VERSION "dbc-export 1 2026.26.6.5"

NS_ :

BS_:

BU_: ADSP APB APP APS APSB BB BMS CC CMP CMPD CP DAS DI DIF DIR DPB EPAS3P EPAS3S EPASTP EPASTS EPBL EPBR ESP EVSE FC GTW HCML HCMR HVP IBST ICR IDB LS OCS1P ODIN PARK PCS PCS2 PLG PM PMF PMR PNCD PTC RADC RCM RCM2 RCM3 RCU SCCM SCM SCS SDCR TAS TCU TCU2 TPMS TRCM UDS UI UIS UMC USM V2G VC VCBATT VCBATT0 VCBATT1 VCBATT2 VCCC VCFRONT VCFRONT1 VCFRONT2 VCLEFT VCRIGHT VCSEAT2L VCSEAT2R VCSEC VEH

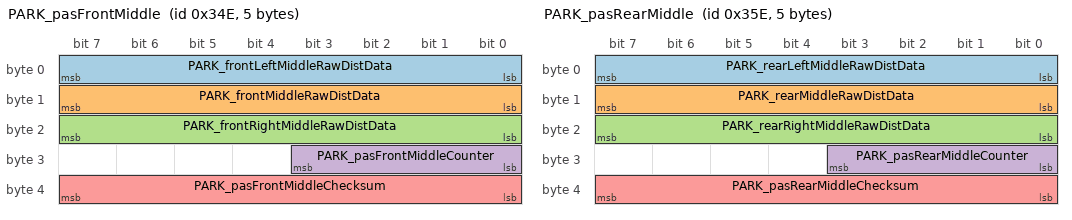
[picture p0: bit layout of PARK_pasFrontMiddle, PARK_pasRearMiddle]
BO_ 846 PARK_pasFrontMiddle: 5 PARK
 SG_ PARK_frontLeftMiddleRawDistData : 0|8@1+ (1,0) [0|254] "cm" Vector__XXX
 SG_ PARK_frontMiddleRawDistData : 8|8@1+ (1,0) [0|254] "cm" Vector__XXX
 SG_ PARK_frontRightMiddleRawDistData : 16|8@1+ (1,0) [0|254] "cm" Vector__XXX
 SG_ PARK_pasFrontMiddleCounter : 24|4@1+ (1,0) [0|15] "" Vector__XXX
 SG_ PARK_pasFrontMiddleChecksum : 32|8@1+ (1,0) [0|255] "" Vector__XXX

BO_ 862 PARK_pasRearMiddle: 5 PARK
 SG_ PARK_rearLeftMiddleRawDistData : 0|8@1+ (1,0) [0|254] "cm" Vector__XXX
 SG_ PARK_rearMiddleRawDistData : 8|8@1+ (1,0) [0|254] "cm" Vector__XXX
 SG_ PARK_rearRightMiddleRawDistData : 16|8@1+ (1,0) [0|254] "cm" Vector__XXX
 SG_ PARK_pasRearMiddleCounter : 24|4@1+ (1,0) [0|15] "" Vector__XXX
 SG_ PARK_pasRearMiddleChecksum : 32|8@1+ (1,0) [0|255] "" Vector__XXX

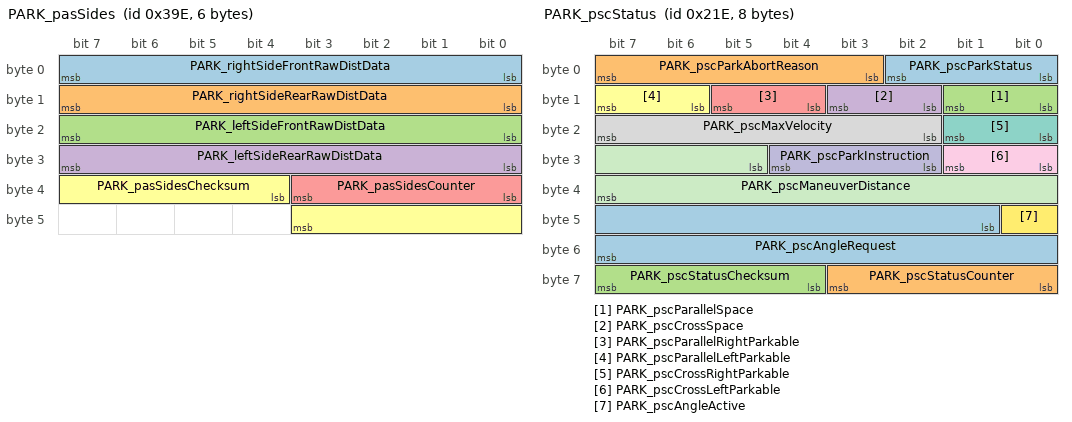
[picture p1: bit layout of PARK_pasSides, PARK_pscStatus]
BO_ 926 PARK_pasSides: 6 PARK
 SG_ PARK_rightSideFrontRawDistData : 0|8@1+ (1,0) [0|254] "cm" Vector__XXX
 SG_ PARK_rightSideRearRawDistData : 8|8@1+ (1,0) [0|254] "cm" Vector__XXX
 SG_ PARK_leftSideFrontRawDistData : 16|8@1+ (1,0) [0|254] "cm" Vector__XXX
 SG_ PARK_leftSideRearRawDistData : 24|8@1+ (1,0) [0|254] "cm" Vector__XXX
 SG_ PARK_pasSidesCounter : 32|4@1+ (1,0) [0|15] "" Vector__XXX
 SG_ PARK_pasSidesChecksum : 36|8@1+ (1,0) [0|255] "" Vector__XXX

BO_ 606 PARK_pscEnvSlot: 8 PARK
 SG_ PARK_pscEnvSlotType M : 0|2@1+ (1,0) [0|3] "" Vector__XXX
 SG_ PARK_pscLeftParallelObj1X m0 : 3|11@1+ (2,-2048) [-2048|2044] "cm" Vector__XXX
 SG_ PARK_pscLeftParallelObj1Y m0 : 14|11@1+ (2,-2048) [-2048|2044] "cm" Vector__XXX
 SG_ PARK_pscLeftParallelObj1Alpha m0 : 25|7@1+ (2,-128) [-128|124] "deg" Vector__XXX
 SG_ PARK_pscLeftParallelObj2Y m0 : 35|11@1+ (2,-2048) [-2048|2044] "cm" Vector__XXX
 SG_ PARK_pscLeftParallelObj2X m0 : 46|11@1+ (2,-2048) [-2048|2044] "cm" Vector__XXX
 SG_ PARK_pscLeftParallelObj2Alpha m0 : 57|7@1+ (2,-128) [-128|124] "deg" Vector__XXX
 SG_ PARK_pscLeftCrossObj1X m1 : 3|11@1+ (2,-2048) [-2048|2044] "cm" Vector__XXX
 SG_ PARK_pscLeftCrossObj1Y m1 : 14|11@1+ (2,-2048) [-2048|2044] "cm" Vector__XXX
 SG_ PARK_pscLeftCrossObj1Alpha m1 : 25|7@1+ (2,-128) [-128|124] "deg" Vector__XXX
 SG_ PARK_pscLeftCrossObj2Y m1 : 35|11@1+ (2,-2048) [-2048|2044] "cm" Vector__XXX
 SG_ PARK_pscLeftCrossObj2X m1 : 46|11@1+ (2,-2048) [-2048|2044] "cm" Vector__XXX
 SG_ PARK_pscLeftCrossObj2Alpha m1 : 57|7@1+ (2,-128) [-128|124] "deg" Vector__XXX
 SG_ PARK_pscRightParallelObj1X m2 : 3|11@1+ (2,-2048) [-2048|2044] "cm" Vector__XXX
 SG_ PARK_pscRightParallelObj1Y m2 : 14|11@1+ (2,-2048) [-2048|2044] "cm" Vector__XXX
 SG_ PARK_pscRightParallelObj1Alpha m2 : 25|7@1+ (2,-128) [-128|124] "deg" Vector__XXX
 SG_ PARK_pscRightParallelObj2Y m2 : 35|11@1+ (2,-2048) [-2048|2044] "cm" Vector__XXX
 SG_ PARK_pscRightParallelObj2X m2 : 46|11@1+ (2,-2048) [-2048|2044] "cm" Vector__XXX
 SG_ PARK_pscRightParallelObj2Alpha m2 : 57|7@1+ (2,-128) [-128|124] "deg" Vector__XXX
 SG_ PARK_pscRightCrossObj1X m3 : 3|11@1+ (2,-2048) [-2048|2044] "cm" Vector__XXX
 SG_ PARK_pscRightCrossObj1Y m3 : 14|11@1+ (2,-2048) [-2048|2044] "cm" Vector__XXX
 SG_ PARK_pscRightCrossObj1Alpha m3 : 25|7@1+ (2,-128) [-128|124] "deg" Vector__XXX
 SG_ PARK_pscRightCrossObj2Y m3 : 35|11@1+ (2,-2048) [-2048|2044] "cm" Vector__XXX
 SG_ PARK_pscRightCrossObj2X m3 : 46|11@1+ (2,-2048) [-2048|2044] "cm" Vector__XXX
 SG_ PARK_pscRightCrossObj2Alpha m3 : 57|7@1+ (2,-128) [-128|124] "deg" Vector__XXX

BO_ 542 PARK_pscStatus: 8 PARK
 SG_ PARK_pscParkStatus : 0|3@1+ (1,0) [0|6] "" Vector__XXX
 SG_ PARK_pscParkAbortReason : 3|5@1+ (1,0) [0|30] "" Vector__XXX
 SG_ PARK_pscParallelSpace : 8|2@1+ (1,0) [0|3] "" Vector__XXX
 SG_ PARK_pscCrossSpace : 10|2@1+ (1,0) [0|3] "" Vector__XXX
 SG_ PARK_pscParallelRightParkable : 12|2@1+ (1,0) [0|2] "" Vector__XXX
 SG_ PARK_pscParallelLeftParkable : 14|2@1+ (1,0) [0|2] "" Vector__XXX
 SG_ PARK_pscCrossRightParkable : 16|2@1+ (1,0) [0|2] "" Vector__XXX
 SG_ PARK_pscMaxVelocity : 18|6@1+ (0.1,0) [0|6.2] "kph" Vector__XXX
 SG_ PARK_pscCrossLeftParkable : 24|2@1+ (1,0) [0|2] "" Vector__XXX
 SG_ PARK_pscParkInstruction : 26|3@1+ (1,0) [0|6] "" Vector__XXX
 SG_ PARK_pscManeuverDistance : 29|11@1+ (1,0) [0|2046] "cm" Vector__XXX
 SG_ PARK_pscAngleActive : 40|1@1+ (1,0) [0|1] "" Vector__XXX
 SG_ PARK_pscAngleRequest : 41|15@1+ (0.1,-1638.4) [-1638.4|1638.3] "deg" Vector__XXX
 SG_ PARK_pscStatusCounter : 56|4@1+ (1,0) [0|15] "" Vector__XXX
 SG_ PARK_pscStatusChecksum : 60|4@1+ (1,0) [0|15] "" Vector__XXX

BO_ 590 PARK_pscVehSlot: 8 PARK
 SG_ PARK_pscVehSlotType M : 0|2@1+ (1,0) [0|3] "" Vector__XXX
 SG_ PARK_pscLeftParallelVehX m0 : 5|11@1+ (2,-2048) [-2048|2044] "cm" Vector__XXX
 SG_ PARK_pscLeftParallelVehY m0 : 16|11@1+ (2,-2048) [-2048|2044] "cm" Vector__XXX
 SG_ PARK_pscLeftParallelPsi m0 : 32|13@1+ (0.0009765625,0) [0|7.998046875] "radians" Vector__XXX
 SG_ PARK_pscLeftParallelSizeX m0 : 48|8@1+ (4,0) [0|1016] "cm" Vector__XXX
 SG_ PARK_pscLeftParallelSizeY m0 : 56|8@1+ (4,0) [0|1016] "cm" Vector__XXX
 SG_ PARK_pscLeftCrossVehX m1 : 5|11@1+ (2,-2048) [-2048|2044] "cm" Vector__XXX
 SG_ PARK_pscLeftCrossVehY m1 : 16|11@1+ (2,-2048) [-2048|2044] "cm" Vector__XXX
 SG_ PARK_pscLeftCrossPsi m1 : 32|13@1+ (0.0009765625,0) [0|7.998046875] "radians" Vector__XXX
 SG_ PARK_pscLeftCrossSizeX m1 : 48|8@1+ (4,0) [0|1016] "cm" Vector__XXX
 SG_ PARK_pscLeftCrossSizeY m1 : 56|8@1+ (4,0) [0|1016] "cm" Vector__XXX
 SG_ PARK_pscRightParallelVehX m2 : 5|11@1+ (2,-2048) [-2048|2044] "cm" Vector__XXX
 SG_ PARK_pscRightParallelVehY m2 : 16|11@1+ (2,-2048) [-2048|2044] "cm" Vector__XXX
 SG_ PARK_pscRightParallelPsi m2 : 32|13@1+ (0.0009765625,0) [0|7.998046875] "radians" Vector__XXX
 SG_ PARK_pscRightParallelSizeX m2 : 48|8@1+ (4,0) [0|1016] "cm" Vector__XXX
 SG_ PARK_pscRightParallelSizeY m2 : 56|8@1+ (4,0) [0|1016] "cm" Vector__XXX
 SG_ PARK_pscRightCrossVehX m3 : 5|11@1+ (2,-2048) [-2048|2044] "cm" Vector__XXX
 SG_ PARK_pscRightCrossVehY m3 : 16|11@1+ (2,-2048) [-2048|2044] "cm" Vector__XXX
 SG_ PARK_pscRightCrossPsi m3 : 32|13@1+ (0.0009765625,0) [0|7.998046875] "radians" Vector__XXX
 SG_ PARK_pscRightCrossSizeX m3 : 48|8@1+ (4,0) [0|1016] "cm" Vector__XXX
 SG_ PARK_pscRightCrossSizeY m3 : 56|8@1+ (4,0) [0|1016] "cm" Vector__XXX

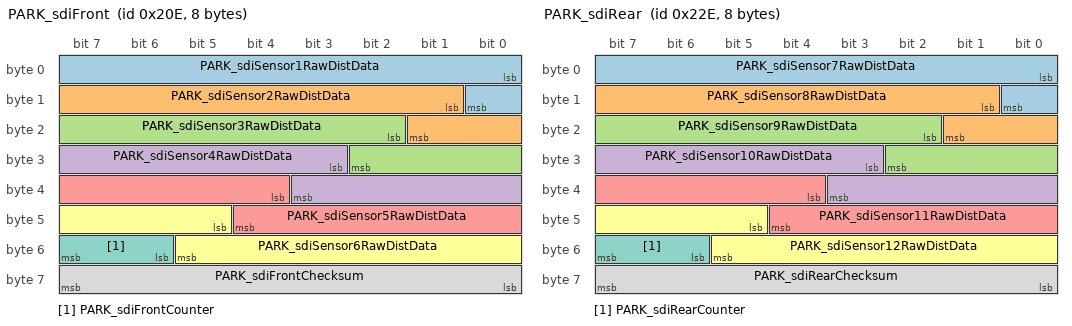
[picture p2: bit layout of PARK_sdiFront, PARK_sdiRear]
BO_ 526 PARK_sdiFront: 8 PARK
 SG_ PARK_sdiSensor1RawDistData : 0|9@1+ (1,0) [0|510] "cm" Vector__XXX
 SG_ PARK_sdiSensor2RawDistData : 9|9@1+ (1,0) [0|510] "cm" Vector__XXX
 SG_ PARK_sdiSensor3RawDistData : 18|9@1+ (1,0) [0|510] "cm" Vector__XXX
 SG_ PARK_sdiSensor4RawDistData : 27|9@1+ (1,0) [0|510] "cm" Vector__XXX
 SG_ PARK_sdiSensor5RawDistData : 36|9@1+ (1,0) [0|510] "cm" Vector__XXX
 SG_ PARK_sdiSensor6RawDistData : 45|9@1+ (1,0) [0|510] "cm" Vector__XXX
 SG_ PARK_sdiFrontCounter : 54|2@1+ (1,0) [0|3] "" Vector__XXX
 SG_ PARK_sdiFrontChecksum : 56|8@1+ (1,0) [0|255] "" Vector__XXX

BO_ 558 PARK_sdiRear: 8 PARK
 SG_ PARK_sdiSensor7RawDistData : 0|9@1+ (1,0) [0|510] "cm" Vector__XXX
 SG_ PARK_sdiSensor8RawDistData : 9|9@1+ (1,0) [0|510] "cm" Vector__XXX
 SG_ PARK_sdiSensor9RawDistData : 18|9@1+ (1,0) [0|510] "cm" Vector__XXX
 SG_ PARK_sdiSensor10RawDistData : 27|9@1+ (1,0) [0|510] "cm" Vector__XXX
 SG_ PARK_sdiSensor11RawDistData : 36|9@1+ (1,0) [0|510] "cm" Vector__XXX
 SG_ PARK_sdiSensor12RawDistData : 45|9@1+ (1,0) [0|510] "cm" Vector__XXX
 SG_ PARK_sdiRearCounter : 54|2@1+ (1,0) [0|3] "" Vector__XXX
 SG_ PARK_sdiRearChecksum : 56|8@1+ (1,0) [0|255] "" Vector__XXX

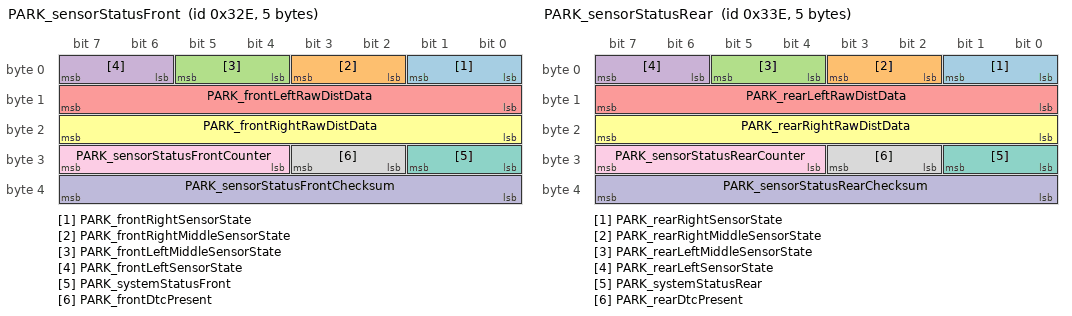
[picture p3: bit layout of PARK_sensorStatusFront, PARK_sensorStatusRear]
BO_ 814 PARK_sensorStatusFront: 5 PARK
 SG_ PARK_frontRightSensorState : 0|2@1+ (1,0) [0|2] "" Vector__XXX
 SG_ PARK_frontRightMiddleSensorState : 2|2@1+ (1,0) [0|2] "" Vector__XXX
 SG_ PARK_frontLeftMiddleSensorState : 4|2@1+ (1,0) [0|2] "" Vector__XXX
 SG_ PARK_frontLeftSensorState : 6|2@1+ (1,0) [0|2] "" Vector__XXX
 SG_ PARK_frontLeftRawDistData : 8|8@1+ (1,0) [0|254] "cm" Vector__XXX
 SG_ PARK_frontRightRawDistData : 16|8@1+ (1,0) [0|254] "cm" Vector__XXX
 SG_ PARK_systemStatusFront : 24|2@1+ (1,0) [0|2] "" Vector__XXX
 SG_ PARK_frontDtcPresent : 26|2@1+ (1,0) [0|2] "" Vector__XXX
 SG_ PARK_sensorStatusFrontCounter : 28|4@1+ (1,0) [0|15] "" Vector__XXX
 SG_ PARK_sensorStatusFrontChecksum : 32|8@1+ (1,0) [0|255] "" Vector__XXX

BO_ 830 PARK_sensorStatusRear: 5 PARK
 SG_ PARK_rearRightSensorState : 0|2@1+ (1,0) [0|2] "" Vector__XXX
 SG_ PARK_rearRightMiddleSensorState : 2|2@1+ (1,0) [0|2] "" Vector__XXX
 SG_ PARK_rearLeftMiddleSensorState : 4|2@1+ (1,0) [0|2] "" Vector__XXX
 SG_ PARK_rearLeftSensorState : 6|2@1+ (1,0) [0|2] "" Vector__XXX
 SG_ PARK_rearLeftRawDistData : 8|8@1+ (1,0) [0|254] "cm" Vector__XXX
 SG_ PARK_rearRightRawDistData : 16|8@1+ (1,0) [0|254] "cm" Vector__XXX
 SG_ PARK_systemStatusRear : 24|2@1+ (1,0) [0|2] "" Vector__XXX
 SG_ PARK_rearDtcPresent : 26|2@1+ (1,0) [0|2] "" Vector__XXX
 SG_ PARK_sensorStatusRearCounter : 28|4@1+ (1,0) [0|15] "" Vector__XXX
 SG_ PARK_sensorStatusRearChecksum : 32|8@1+ (1,0) [0|255] "" Vector__XXX

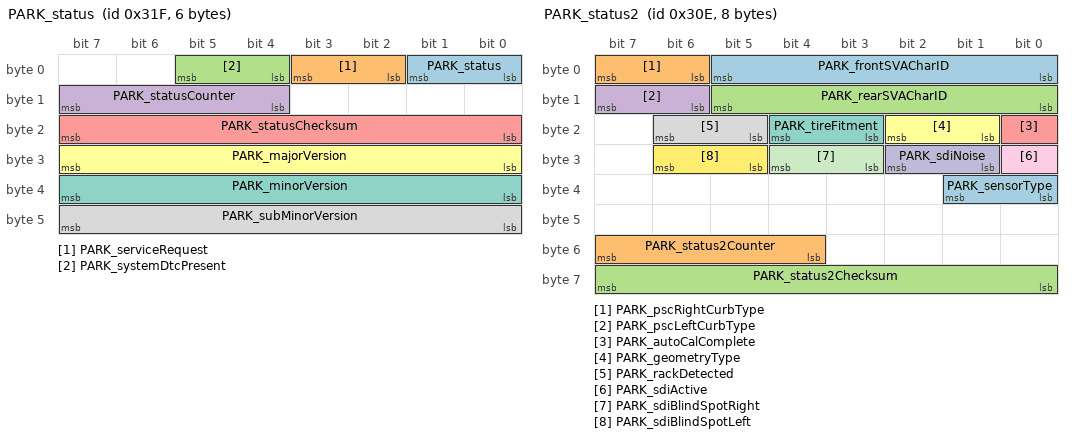
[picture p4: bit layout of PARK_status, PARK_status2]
BO_ 799 PARK_status: 6 PARK
 SG_ PARK_status : 0|2@1+ (1,0) [0|2] "" Vector__XXX
 SG_ PARK_serviceRequest : 2|2@1+ (1,0) [0|2] "" Vector__XXX
 SG_ PARK_systemDtcPresent : 4|2@1+ (1,0) [0|2] "" Vector__XXX
 SG_ PARK_statusCounter : 12|4@1+ (1,0) [0|15] "" Vector__XXX
 SG_ PARK_statusChecksum : 16|8@1+ (1,0) [0|255] "" Vector__XXX
 SG_ PARK_majorVersion : 24|8@1+ (1,0) [0|254] "" Vector__XXX
 SG_ PARK_minorVersion : 32|8@1+ (1,0) [0|254] "" Vector__XXX
 SG_ PARK_subMinorVersion : 40|8@1+ (1,0) [0|254] "" Vector__XXX

BO_ 782 PARK_status2: 8 PARK
 SG_ PARK_frontSVACharID : 0|6@1+ (1,0) [0|63] "" Vector__XXX
 SG_ PARK_pscRightCurbType : 6|2@1+ (1,0) [0|3] "" Vector__XXX
 SG_ PARK_rearSVACharID : 8|6@1+ (1,0) [0|63] "" Vector__XXX
 SG_ PARK_pscLeftCurbType : 14|2@1+ (1,0) [0|3] "" Vector__XXX
 SG_ PARK_autoCalComplete : 16|1@1+ (1,0) [0|1] "" Vector__XXX
 SG_ PARK_geometryType : 17|2@1+ (1,0) [0|3] "" Vector__XXX
 SG_ PARK_tireFitment : 19|2@1+ (1,0) [0|2] "" Vector__XXX
 SG_ PARK_rackDetected : 21|2@1+ (1,0) [0|2] "" Vector__XXX
 SG_ PARK_sdiActive : 24|1@1+ (1,0) [0|1] "" Vector__XXX
 SG_ PARK_sdiNoise : 25|2@1+ (1,0) [0|2] "" Vector__XXX
 SG_ PARK_sdiBlindSpotRight : 27|2@1+ (1,0) [0|2] "" Vector__XXX
 SG_ PARK_sdiBlindSpotLeft : 29|2@1+ (1,0) [0|2] "" Vector__XXX
 SG_ PARK_sensorType : 32|2@1+ (1,0) [0|2] "" Vector__XXX
 SG_ PARK_status2Counter : 52|4@1+ (1,0) [0|15] "" Vector__XXX
 SG_ PARK_status2Checksum : 56|8@1+ (1,0) [0|255] "" Vector__XXX

BO_ 1630 PARK_udsResponse: 8 PARK
 SG_ PARK_udsResponseData : 0|64@1+ (1,0) [0|1.84467440737e+19] "" Vector__XXX

BO_ 894 PARK_warningMatrix: 8 PARK
 SG_ PARK_matrixIndex M : 0|4@1+ (1,0) [0|15] "" Vector__XXX
 SG_ PARK_a001_s1_overTemp m0 : 4|1@1+ (1,0) [0|1] "" Vector__XXX
 SG_ PARK_a002_s1_internalFail m0 : 5|1@1+ (1,0) [0|1] "" Vector__XXX
 SG_ PARK_a003_s1_linCommError m0 : 6|1@1+ (1,0) [0|1] "" Vector__XXX
 SG_ PARK_a004_s1_blocked m0 : 7|1@1+ (1,0) [0|1] "" Vector__XXX
 SG_ PARK_a005_s1_crossTalk m0 : 8|1@1+ (1,0) [0|1] "" Vector__XXX
 SG_ PARK_a006_s2_overTemp m0 : 9|1@1+ (1,0) [0|1] "" Vector__XXX
 SG_ PARK_a007_s2_internalFail m0 : 10|1@1+ (1,0) [0|1] "" Vector__XXX
 SG_ PARK_a008_s2_linCommError m0 : 11|1@1+ (1,0) [0|1] "" Vector__XXX
 SG_ PARK_a009_s2_blocked m0 : 12|1@1+ (1,0) [0|1] "" Vector__XXX
 SG_ PARK_a010_s2_crossTalk m0 : 13|1@1+ (1,0) [0|1] "" Vector__XXX
 SG_ PARK_a011_s3_overTemp m0 : 14|1@1+ (1,0) [0|1] "" Vector__XXX
 SG_ PARK_a012_s3_internalFail m0 : 15|1@1+ (1,0) [0|1] "" Vector__XXX
 SG_ PARK_a013_s3_linCommError m0 : 16|1@1+ (1,0) [0|1] "" Vector__XXX
 SG_ PARK_a014_s3_blocked m0 : 17|1@1+ (1,0) [0|1] "" Vector__XXX
 SG_ PARK_a015_s3_crossTalk m0 : 18|1@1+ (1,0) [0|1] "" Vector__XXX
 SG_ PARK_a016_s4_overTemp m0 : 19|1@1+ (1,0) [0|1] "" Vector__XXX
 SG_ PARK_a017_s4_internalFail m0 : 20|1@1+ (1,0) [0|1] "" Vector__XXX
 SG_ PARK_a018_s4_linCommError m0 : 21|1@1+ (1,0) [0|1] "" Vector__XXX
 SG_ PARK_a019_s4_blocked m0 : 22|1@1+ (1,0) [0|1] "" Vector__XXX
 SG_ PARK_a020_s4_crossTalk m0 : 23|1@1+ (1,0) [0|1] "" Vector__XXX
 SG_ PARK_a021_s5_overTemp m0 : 24|1@1+ (1,0) [0|1] "" Vector__XXX
 SG_ PARK_a022_s5_internalFail m0 : 25|1@1+ (1,0) [0|1] "" Vector__XXX
 SG_ PARK_a023_s5_linCommError m0 : 26|1@1+ (1,0) [0|1] "" Vector__XXX
 SG_ PARK_a024_s5_blocked m0 : 27|1@1+ (1,0) [0|1] "" Vector__XXX
 SG_ PARK_a025_s5_crossTalk m0 : 28|1@1+ (1,0) [0|1] "" Vector__XXX
 SG_ PARK_a026_s6_overTemp m0 : 29|1@1+ (1,0) [0|1] "" Vector__XXX
 SG_ PARK_a027_s6_internalFail m0 : 30|1@1+ (1,0) [0|1] "" Vector__XXX
 SG_ PARK_a028_s6_linCommError m0 : 31|1@1+ (1,0) [0|1] "" Vector__XXX
 SG_ PARK_a029_s6_blocked m0 : 32|1@1+ (1,0) [0|1] "" Vector__XXX
 SG_ PARK_a030_s6_crossTalk m0 : 33|1@1+ (1,0) [0|1] "" Vector__XXX
 SG_ PARK_a031_s7_overTemp m0 : 34|1@1+ (1,0) [0|1] "" Vector__XXX
 SG_ PARK_a032_s7_internalFail m0 : 35|1@1+ (1,0) [0|1] "" Vector__XXX
 SG_ PARK_a033_s7_linCommError m0 : 36|1@1+ (1,0) [0|1] "" Vector__XXX
 SG_ PARK_a034_s7_blocked m0 : 37|1@1+ (1,0) [0|1] "" Vector__XXX
 SG_ PARK_a035_s7_crossTalk m0 : 38|1@1+ (1,0) [0|1] "" Vector__XXX
 SG_ PARK_a036_s8_overTemp m0 : 39|1@1+ (1,0) [0|1] "" Vector__XXX
 SG_ PARK_a037_s8_internalFail m0 : 40|1@1+ (1,0) [0|1] "" Vector__XXX
 SG_ PARK_a038_s8_linCommError m0 : 41|1@1+ (1,0) [0|1] "" Vector__XXX
 SG_ PARK_a039_s8_blocked m0 : 42|1@1+ (1,0) [0|1] "" Vector__XXX
 SG_ PARK_a040_s8_crossTalk m0 : 43|1@1+ (1,0) [0|1] "" Vector__XXX
 SG_ PARK_a041_s9_overTemp m0 : 44|1@1+ (1,0) [0|1] "" Vector__XXX
 SG_ PARK_a042_s9_internalFail m0 : 45|1@1+ (1,0) [0|1] "" Vector__XXX
 SG_ PARK_a043_s9_linCommError m0 : 46|1@1+ (1,0) [0|1] "" Vector__XXX
 SG_ PARK_a044_s9_blocked m0 : 47|1@1+ (1,0) [0|1] "" Vector__XXX
 SG_ PARK_a045_s9_crossTalk m0 : 48|1@1+ (1,0) [0|1] "" Vector__XXX
 SG_ PARK_a046_s10_overTemp m0 : 49|1@1+ (1,0) [0|1] "" Vector__XXX
 SG_ PARK_a047_s10_internalFail m0 : 50|1@1+ (1,0) [0|1] "" Vector__XXX
 SG_ PARK_a048_s10_linCommError m0 : 51|1@1+ (1,0) [0|1] "" Vector__XXX
 SG_ PARK_a049_s10_blocked m0 : 52|1@1+ (1,0) [0|1] "" Vector__XXX
 SG_ PARK_a050_s10_crossTalk m0 : 53|1@1+ (1,0) [0|1] "" Vector__XXX
 SG_ PARK_a051_s11_overTemp m0 : 54|1@1+ (1,0) [0|1] "" Vector__XXX
 SG_ PARK_a052_s11_internalFail m0 : 55|1@1+ (1,0) [0|1] "" Vector__XXX
 SG_ PARK_a053_s11_linCommError m0 : 56|1@1+ (1,0) [0|1] "" Vector__XXX
 SG_ PARK_a054_s11_blocked m0 : 57|1@1+ (1,0) [0|1] "" Vector__XXX
 SG_ PARK_a055_s11_crossTalk m0 : 58|1@1+ (1,0) [0|1] "" Vector__XXX
 SG_ PARK_a056_s12_overTemp m0 : 59|1@1+ (1,0) [0|1] "" Vector__XXX
 SG_ PARK_a057_s12_internalFail m0 : 60|1@1+ (1,0) [0|1] "" Vector__XXX
 SG_ PARK_a058_s12_linCommError m0 : 61|1@1+ (1,0) [0|1] "" Vector__XXX
 SG_ PARK_a059_s12_blocked m0 : 62|1@1+ (1,0) [0|1] "" Vector__XXX
 SG_ PARK_a060_s12_crossTalk m0 : 63|1@1+ (1,0) [0|1] "" Vector__XXX
 SG_ PARK_a061_ecuUnderVoltage m1 : 4|1@1+ (1,0) [0|1] "" Vector__XXX
 SG_ PARK_a062_ecuOverVoltage m1 : 5|1@1+ (1,0) [0|1] "" Vector__XXX
 SG_ PARK_a063_sensorVoltage m1 : 6|1@1+ (1,0) [0|1] "" Vector__XXX
 SG_ PARK_a064_ecuFault m1 : 7|1@1+ (1,0) [0|1] "" Vector__XXX
 SG_ PARK_a065_crcFault m1 : 8|1@1+ (1,0) [0|1] "" Vector__XXX
 SG_ PARK_a066_calibrationMissing m1 : 9|1@1+ (1,0) [0|1] "" Vector__XXX
 SG_ PARK_a067_privateCANBusOff m1 : 10|1@1+ (1,0) [0|1] "" Vector__XXX
 SG_ PARK_a068_hardwareWatchDog m1 : 11|1@1+ (1,0) [0|1] "" Vector__XXX
 SG_ PARK_a069_dasMia m1 : 12|1@1+ (1,0) [0|1] "" Vector__XXX
 SG_ PARK_a070_sccmMia m1 : 13|1@1+ (1,0) [0|1] "" Vector__XXX
 SG_ PARK_a071_diMia m1 : 14|1@1+ (1,0) [0|1] "" Vector__XXX
 SG_ PARK_a072_epasMia m1 : 15|1@1+ (1,0) [0|1] "" Vector__XXX
 SG_ PARK_a073_epbMia m1 : 16|1@1+ (1,0) [0|1] "" Vector__XXX
 SG_ PARK_a074_espMia m1 : 17|1@1+ (1,0) [0|1] "" Vector__XXX
 SG_ PARK_a075_rcmMia m1 : 18|1@1+ (1,0) [0|1] "" Vector__XXX
 SG_ PARK_a076_vcFrontMia m1 : 19|1@1+ (1,0) [0|1] "" Vector__XXX
 SG_ PARK_a077_dasError m1 : 20|1@1+ (1,0) [0|1] "" Vector__XXX
 SG_ PARK_a078_diError m1 : 21|1@1+ (1,0) [0|1] "" Vector__XXX
 SG_ PARK_a079_epasError m1 : 22|1@1+ (1,0) [0|1] "" Vector__XXX
 SG_ PARK_a080_epbError m1 : 23|1@1+ (1,0) [0|1] "" Vector__XXX
 SG_ PARK_a081_espError m1 : 24|1@1+ (1,0) [0|1] "" Vector__XXX
 SG_ PARK_a082_rcmError m1 : 25|1@1+ (1,0) [0|1] "" Vector__XXX
 SG_ PARK_a083_vcFrontError m1 : 26|1@1+ (1,0) [0|1] "" Vector__XXX
 SG_ PARK_a084_sccmError m1 : 27|1@1+ (1,0) [0|1] "" Vector__XXX
 SG_ PARK_a085_watchdogReset m1 : 28|1@1+ (1,0) [0|1] "" Vector__XXX
 SG_ PARK_a086_nvmFault m1 : 29|1@1+ (1,0) [0|1] "" Vector__XXX
 SG_ PARK_a087_sensorMismatchError m1 : 30|1@1+ (1,0) [0|1] "" Vector__XXX

BO_TX_BU_ 846 : PARK;
BO_TX_BU_ 862 : PARK;
BO_TX_BU_ 926 : PARK;
BO_TX_BU_ 606 : PARK;
BO_TX_BU_ 542 : PARK;
BO_TX_BU_ 590 : PARK;
BO_TX_BU_ 526 : PARK;
BO_TX_BU_ 558 : PARK;
BO_TX_BU_ 814 : PARK;
BO_TX_BU_ 830 : PARK;
BO_TX_BU_ 799 : PARK;
BO_TX_BU_ 782 : PARK;
BO_TX_BU_ 1630 : PARK;
BO_TX_BU_ 894 : PARK;
CM_ BO_ 846 "Parking assist sensors message: pas front middle";
CM_ SG_ 846 PARK_frontLeftMiddleRawDistData "Zone defined as -38 degrees -> +12 degrees, distance to object in units of centimeters; raw 255 = signal not available (SNA)";
CM_ SG_ 846 PARK_frontMiddleRawDistData "Zone defined as -12 degrees to +12 degrees, distance to object in units of centimeters; raw 255 = signal not available (SNA)";
CM_ SG_ 846 PARK_frontRightMiddleRawDistData "Zone defined +12 degrees to +38 degreees, distance to object in units of centimeters; raw 255 = signal not available (SNA)";
CM_ SG_ 846 PARK_pasFrontMiddleCounter "Parking assist sensors: pas front middle counter";
CM_ SG_ 846 PARK_pasFrontMiddleChecksum "Parking assist sensors: pas front middle checksum";
CM_ BO_ 862 "Parking assist sensors message: pas rear middle";
CM_ SG_ 862 PARK_rearLeftMiddleRawDistData "Zone defined as -124 degrees to -166 degrees, distance to object in units of centimeters; raw 255 = signal not available (SNA)";
CM_ SG_ 862 PARK_rearMiddleRawDistData "Zone defined as -166 degrees to +166 degrees, distance to object in units of centimeters; raw 255 = signal not available (SNA)";
CM_ SG_ 862 PARK_rearRightMiddleRawDistData "Zone defined as +166 degrees to +124 degrees, distance to object in units of centimeters; raw 255 = signal not available (SNA)";
CM_ SG_ 862 PARK_pasRearMiddleCounter "Parking assist sensors: pas rear middle counter";
CM_ SG_ 862 PARK_pasRearMiddleChecksum "Parking assist sensors: pas rear middle checksum";
CM_ BO_ 926 "Parking assist sensors message: pas sides";
CM_ SG_ 926 PARK_rightSideFrontRawDistData "Right side (from inside the car) towards the front of the car (split evenly between axles); raw 255 = signal not available (SNA)";
CM_ SG_ 926 PARK_rightSideRearRawDistData "Right side (from inside the car) towards the rear of the car (split evenly between axles); raw 255 = signal not available (SNA)";
CM_ SG_ 926 PARK_leftSideFrontRawDistData "Left side (from inside the car) towards the front of the car (split evenly between axles); raw 255 = signal not available (SNA)";
CM_ SG_ 926 PARK_leftSideRearRawDistData "Left side (from inside the car) towards the rear of the car (split evenly between axles); raw 255 = signal not available (SNA)";
CM_ SG_ 926 PARK_pasSidesCounter "Parking assist sensors: pas sides counter";
CM_ SG_ 926 PARK_pasSidesChecksum "Parking assist sensors: pas sides checksum";
CM_ BO_ 606 "Parking assist sensors message: psc env slot";
CM_ SG_ 606 PARK_pscEnvSlotType "Parking assist sensors: psc env slot type";
CM_ SG_ 606 PARK_pscLeftParallelObj1X "Parking assist sensors: psc left parallel obj1 x; raw 2047 = signal not available (SNA)";
CM_ SG_ 606 PARK_pscLeftParallelObj1Y "Parking assist sensors: psc left parallel obj1 y; raw 2047 = signal not available (SNA)";
CM_ SG_ 606 PARK_pscLeftParallelObj1Alpha "Parking assist sensors: psc left parallel obj1 alpha; raw 127 = signal not available (SNA)";
CM_ SG_ 606 PARK_pscLeftParallelObj2Y "Parking assist sensors: psc left parallel obj2 y; raw 2047 = signal not available (SNA)";
CM_ SG_ 606 PARK_pscLeftParallelObj2X "Parking assist sensors: psc left parallel obj2 x; raw 2047 = signal not available (SNA)";
CM_ SG_ 606 PARK_pscLeftParallelObj2Alpha "Parking assist sensors: psc left parallel obj2 alpha; raw 127 = signal not available (SNA)";
CM_ SG_ 606 PARK_pscLeftCrossObj1X "Parking assist sensors: psc left cross obj1 x; raw 2047 = signal not available (SNA)";
CM_ SG_ 606 PARK_pscLeftCrossObj1Y "Parking assist sensors: psc left cross obj1 y; raw 2047 = signal not available (SNA)";
CM_ SG_ 606 PARK_pscLeftCrossObj1Alpha "Parking assist sensors: psc left cross obj1 alpha; raw 127 = signal not available (SNA)";
CM_ SG_ 606 PARK_pscLeftCrossObj2Y "Parking assist sensors: psc left cross obj2 y; raw 2047 = signal not available (SNA)";
CM_ SG_ 606 PARK_pscLeftCrossObj2X "Parking assist sensors: psc left cross obj2 x; raw 2047 = signal not available (SNA)";
CM_ SG_ 606 PARK_pscLeftCrossObj2Alpha "Parking assist sensors: psc left cross obj2 alpha; raw 127 = signal not available (SNA)";
CM_ SG_ 606 PARK_pscRightParallelObj1X "Parking assist sensors: psc right parallel obj1 x; raw 2047 = signal not available (SNA)";
CM_ SG_ 606 PARK_pscRightParallelObj1Y "Parking assist sensors: psc right parallel obj1 y; raw 2047 = signal not available (SNA)";
CM_ SG_ 606 PARK_pscRightParallelObj1Alpha "Parking assist sensors: psc right parallel obj1 alpha; raw 127 = signal not available (SNA)";
CM_ SG_ 606 PARK_pscRightParallelObj2Y "Parking assist sensors: psc right parallel obj2 y; raw 2047 = signal not available (SNA)";
CM_ SG_ 606 PARK_pscRightParallelObj2X "Parking assist sensors: psc right parallel obj2 x; raw 2047 = signal not available (SNA)";
CM_ SG_ 606 PARK_pscRightParallelObj2Alpha "Parking assist sensors: psc right parallel obj2 alpha; raw 127 = signal not available (SNA)";
CM_ SG_ 606 PARK_pscRightCrossObj1X "Parking assist sensors: psc right cross obj1 x; raw 2047 = signal not available (SNA)";
CM_ SG_ 606 PARK_pscRightCrossObj1Y "Parking assist sensors: psc right cross obj1 y; raw 2047 = signal not available (SNA)";
CM_ SG_ 606 PARK_pscRightCrossObj1Alpha "Parking assist sensors: psc right cross obj1 alpha; raw 127 = signal not available (SNA)";
CM_ SG_ 606 PARK_pscRightCrossObj2Y "Parking assist sensors: psc right cross obj2 y; raw 2047 = signal not available (SNA)";
CM_ SG_ 606 PARK_pscRightCrossObj2X "Parking assist sensors: psc right cross obj2 x; raw 2047 = signal not available (SNA)";
CM_ SG_ 606 PARK_pscRightCrossObj2Alpha "Parking assist sensors: psc right cross obj2 alpha; raw 127 = signal not available (SNA)";
CM_ BO_ 542 "Parking assist sensors message: psc status";
CM_ SG_ 542 PARK_pscParkStatus "Parking assist sensors: psc park status; raw 7 = signal not available (SNA)";
CM_ SG_ 542 PARK_pscParkAbortReason "Parking assist sensors: psc park abort reason; raw 31 = signal not available (SNA)";
CM_ SG_ 542 PARK_pscParallelSpace "The existence and type of a parallel parking slot identified by the ultrasonics.";
CM_ SG_ 542 PARK_pscCrossSpace "The type and existence of perpendicular parking slot identified through the ultrasonics";
CM_ SG_ 542 PARK_pscParallelRightParkable "Whether or not there is a valid path into a parallel parking slot on the right; raw 3 = signal not available (SNA)";
CM_ SG_ 542 PARK_pscParallelLeftParkable "Whether or not there is a valid path into a parallel parking slot on the left; raw 3 = signal not available (SNA)";
CM_ SG_ 542 PARK_pscCrossRightParkable "Parking assist sensors: psc cross right parkable; raw 3 = signal not available (SNA)";
CM_ SG_ 542 PARK_pscMaxVelocity "Parking assist sensors: psc max velocity; raw 63 = signal not available (SNA)";
CM_ SG_ 542 PARK_pscCrossLeftParkable "Parking assist sensors: psc cross left parkable; raw 3 = signal not available (SNA)";
CM_ SG_ 542 PARK_pscParkInstruction "The control request from PARK ECU during autopark manuever; raw 7 = signal not available (SNA)";
CM_ SG_ 542 PARK_pscManeuverDistance "Real time updated path length from center of vehicle reference frame to desired center of vehicle at end of current parking manuever; raw 2047 = signal not available (SNA)";
CM_ SG_ 542 PARK_pscAngleActive "Parking assist sensors: psc angle active";
CM_ SG_ 542 PARK_pscAngleRequest "Parking assist sensors: psc angle request";
CM_ SG_ 542 PARK_pscStatusCounter "Parking assist sensors: psc status counter";
CM_ SG_ 542 PARK_pscStatusChecksum "Parking assist sensors: psc status checksum";
CM_ BO_ 590 "Parking assist sensors message: psc veh slot";
CM_ SG_ 590 PARK_pscVehSlotType "Parking assist sensors: psc veh slot type";
CM_ SG_ 590 PARK_pscLeftParallelVehX "Parking assist sensors: psc left parallel veh x; raw 2047 = signal not available (SNA)";
CM_ SG_ 590 PARK_pscLeftParallelVehY "Parking assist sensors: psc left parallel veh y; raw 2047 = signal not available (SNA)";
CM_ SG_ 590 PARK_pscLeftParallelPsi "Parking assist sensors: psc left parallel psi; raw 8191 = signal not available (SNA)";
CM_ SG_ 590 PARK_pscLeftParallelSizeX "Parking assist sensors: psc left parallel size x; raw 255 = signal not available (SNA)";
CM_ SG_ 590 PARK_pscLeftParallelSizeY "Parking assist sensors: psc left parallel size y; raw 255 = signal not available (SNA)";
CM_ SG_ 590 PARK_pscLeftCrossVehX "Parking assist sensors: psc left cross veh x; raw 2047 = signal not available (SNA)";
CM_ SG_ 590 PARK_pscLeftCrossVehY "Parking assist sensors: psc left cross veh y; raw 2047 = signal not available (SNA)";
CM_ SG_ 590 PARK_pscLeftCrossPsi "Parking assist sensors: psc left cross psi; raw 8191 = signal not available (SNA)";
CM_ SG_ 590 PARK_pscLeftCrossSizeX "Parking assist sensors: psc left cross size x; raw 255 = signal not available (SNA)";
CM_ SG_ 590 PARK_pscLeftCrossSizeY "Parking assist sensors: psc left cross size y; raw 255 = signal not available (SNA)";
CM_ SG_ 590 PARK_pscRightParallelVehX "Parking assist sensors: psc right parallel veh x; raw 2047 = signal not available (SNA)";
CM_ SG_ 590 PARK_pscRightParallelVehY "Parking assist sensors: psc right parallel veh y; raw 2047 = signal not available (SNA)";
CM_ SG_ 590 PARK_pscRightParallelPsi "Parking assist sensors: psc right parallel psi; raw 8191 = signal not available (SNA)";
CM_ SG_ 590 PARK_pscRightParallelSizeX "Parking assist sensors: psc right parallel size x; raw 255 = signal not available (SNA)";
CM_ SG_ 590 PARK_pscRightParallelSizeY "Parking assist sensors: psc right parallel size y; raw 255 = signal not available (SNA)";
CM_ SG_ 590 PARK_pscRightCrossVehX "Parking assist sensors: psc right cross veh x; raw 2047 = signal not available (SNA)";
CM_ SG_ 590 PARK_pscRightCrossVehY "Parking assist sensors: psc right cross veh y; raw 2047 = signal not available (SNA)";
CM_ SG_ 590 PARK_pscRightCrossPsi "Parking assist sensors: psc right cross psi; raw 8191 = signal not available (SNA)";
CM_ SG_ 590 PARK_pscRightCrossSizeX "Parking assist sensors: psc right cross size x; raw 255 = signal not available (SNA)";
CM_ SG_ 590 PARK_pscRightCrossSizeY "Parking assist sensors: psc right cross size y; raw 255 = signal not available (SNA)";
CM_ BO_ 526 "Parking assist sensors message: sdi front";
CM_ SG_ 526 PARK_sdiSensor1RawDistData "Parking assist sensors: sdi sensor1 raw dist data; raw 511 = signal not available (SNA)";
CM_ SG_ 526 PARK_sdiSensor2RawDistData "Parking assist sensors: sdi sensor2 raw dist data; raw 511 = signal not available (SNA)";
CM_ SG_ 526 PARK_sdiSensor3RawDistData "Parking assist sensors: sdi sensor3 raw dist data; raw 511 = signal not available (SNA)";
CM_ SG_ 526 PARK_sdiSensor4RawDistData "Parking assist sensors: sdi sensor4 raw dist data; raw 511 = signal not available (SNA)";
CM_ SG_ 526 PARK_sdiSensor5RawDistData "Parking assist sensors: sdi sensor5 raw dist data; raw 511 = signal not available (SNA)";
CM_ SG_ 526 PARK_sdiSensor6RawDistData "Parking assist sensors: sdi sensor6 raw dist data; raw 511 = signal not available (SNA)";
CM_ SG_ 526 PARK_sdiFrontCounter "Parking assist sensors: sdi front counter";
CM_ SG_ 526 PARK_sdiFrontChecksum "Parking assist sensors: sdi front checksum";
CM_ BO_ 558 "Parking assist sensors message: sdi rear";
CM_ SG_ 558 PARK_sdiSensor7RawDistData "Parking assist sensors: sdi sensor7 raw dist data; raw 511 = signal not available (SNA)";
CM_ SG_ 558 PARK_sdiSensor8RawDistData "Parking assist sensors: sdi sensor8 raw dist data; raw 511 = signal not available (SNA)";
CM_ SG_ 558 PARK_sdiSensor9RawDistData "Parking assist sensors: sdi sensor9 raw dist data; raw 511 = signal not available (SNA)";
CM_ SG_ 558 PARK_sdiSensor10RawDistData "Parking assist sensors: sdi sensor10 raw dist data; raw 511 = signal not available (SNA)";
CM_ SG_ 558 PARK_sdiSensor11RawDistData "Parking assist sensors: sdi sensor11 raw dist data; raw 511 = signal not available (SNA)";
CM_ SG_ 558 PARK_sdiSensor12RawDistData "Parking assist sensors: sdi sensor12 raw dist data; raw 511 = signal not available (SNA)";
CM_ SG_ 558 PARK_sdiRearCounter "Parking assist sensors: sdi rear counter";
CM_ SG_ 558 PARK_sdiRearChecksum "Parking assist sensors: sdi rear checksum";
CM_ BO_ 814 "Parking assist sensors message: sensor status front";
CM_ SG_ 814 PARK_frontRightSensorState "Reports the state of the front right ultrasonic sensor; raw 3 = signal not available (SNA)";
CM_ SG_ 814 PARK_frontRightMiddleSensorState "Reports the state of the front right middle ultrasonic sensor; raw 3 = signal not available (SNA)";
CM_ SG_ 814 PARK_frontLeftMiddleSensorState "Reports the state of the front left middle ultrasonic sensor; raw 3 = signal not available (SNA)";
CM_ SG_ 814 PARK_frontLeftSensorState "Reports the state of the front left ultrasonic sensor; raw 3 = signal not available (SNA)";
CM_ SG_ 814 PARK_frontLeftRawDistData "Zone defined as -90 degrees -> -38 degrees, distance to object in units of centimeters; raw 255 = signal not available (SNA)";
CM_ SG_ 814 PARK_frontRightRawDistData "Zone defined as +38 degrees -> +90 degrees, distance to object in units of centimeters; raw 255 = signal not available (SNA)";
CM_ SG_ 814 PARK_systemStatusFront "Parking assist sensors: system status front; raw 3 = signal not available (SNA)";
CM_ SG_ 814 PARK_frontDtcPresent "Parking assist sensors: front dtc present; raw 3 = signal not available (SNA)";
CM_ SG_ 814 PARK_sensorStatusFrontCounter "Parking assist sensors: sensor status front counter";
CM_ SG_ 814 PARK_sensorStatusFrontChecksum "Parking assist sensors: sensor status front checksum";
CM_ BO_ 830 "Parking assist sensors message: sensor status rear";
CM_ SG_ 830 PARK_rearRightSensorState "Reports the state of the rear right ultrasonic sensor; raw 3 = signal not available (SNA)";
CM_ SG_ 830 PARK_rearRightMiddleSensorState "Reports the state of the rear right middle ultrasonic sensor; raw 3 = signal not available (SNA)";
CM_ SG_ 830 PARK_rearLeftMiddleSensorState "Reports the state of the rear left middle ultrasonic sensor; raw 3 = signal not available (SNA)";
CM_ SG_ 830 PARK_rearLeftSensorState "Reports the state of the rear left ultrasonic sensor; raw 3 = signal not available (SNA)";
CM_ SG_ 830 PARK_rearLeftRawDistData "Zone defined as -90 degrees to -125 degrees, distance to object in units of centimeters; raw 255 = signal not available (SNA)";
CM_ SG_ 830 PARK_rearRightRawDistData "Zone defined as +125 degrees to +90 degrees, distance to object in units of centimeters; raw 255 = signal not available (SNA)";
CM_ SG_ 830 PARK_systemStatusRear "Parking assist sensors: system status rear; raw 3 = signal not available (SNA)";
CM_ SG_ 830 PARK_rearDtcPresent "Parking assist sensors: rear dtc present; raw 3 = signal not available (SNA)";
CM_ SG_ 830 PARK_sensorStatusRearCounter "Parking assist sensors: sensor status rear counter";
CM_ SG_ 830 PARK_sensorStatusRearChecksum "Parking assist sensors: sensor status rear checksum";
CM_ BO_ 799 "Parking assist sensors message: status";
CM_ SG_ 799 PARK_status "Indicates status of park assist function; raw 3 = signal not available (SNA)";
CM_ SG_ 799 PARK_serviceRequest "Indicates whether or not PARK sensors/ECU require service; raw 3 = signal not available (SNA)";
CM_ SG_ 799 PARK_systemDtcPresent "Boolean indicating whether or not there is a DTC present; raw 3 = signal not available (SNA)";
CM_ SG_ 799 PARK_statusCounter "Parking assist sensors: status counter";
CM_ SG_ 799 PARK_statusChecksum "Parking assist sensors: status checksum";
CM_ SG_ 799 PARK_majorVersion "Parking assist sensors: major version; raw 255 = signal not available (SNA)";
CM_ SG_ 799 PARK_minorVersion "Parking assist sensors: minor version; raw 255 = signal not available (SNA)";
CM_ SG_ 799 PARK_subMinorVersion "Parking assist sensors: sub minor version; raw 255 = signal not available (SNA)";
CM_ BO_ 782 "Parking assist sensors message: status2";
CM_ SG_ 782 PARK_frontSVACharID "Parking assist sensors: front SVA char ID";
CM_ SG_ 782 PARK_pscRightCurbType "The type of curb for the parallel parking slot on the right side.";
CM_ SG_ 782 PARK_rearSVACharID "Parking assist sensors: rear SVA char ID";
CM_ SG_ 782 PARK_pscLeftCurbType "The type of curb identified for a parallel parking space on the left.";
CM_ SG_ 782 PARK_autoCalComplete "Parking assist sensors: auto cal complete";
CM_ SG_ 782 PARK_geometryType "Parking assist sensors: geometry type";
CM_ SG_ 782 PARK_tireFitment "Parking assist sensors: tire fitment; raw 3 = signal not available (SNA)";
CM_ SG_ 782 PARK_rackDetected "Parking assist sensors: rack detected; raw 3 = signal not available (SNA)";
CM_ SG_ 782 PARK_sdiActive "Whether or not the raw sensor measurements from the ultrasonics are present and valid";
CM_ SG_ 782 PARK_sdiNoise "The output of the noise detection algorithm for raw sensor measurements, indicates if the measurements are degraded due to ambient noise; raw 3 = signal not available (SNA)";
CM_ SG_ 782 PARK_sdiBlindSpotRight "The output of the PARK ECU blindspot algorithm on the right side of the car, indicates the presence of a vehicle; raw 3 = signal not available (SNA)";
CM_ SG_ 782 PARK_sdiBlindSpotLeft "The output of the PARK ECU blindspot algorithm on the left side of the car, indicates the presence of a vehicle; raw 3 = signal not available (SNA)";
CM_ SG_ 782 PARK_sensorType "Parking assist sensors: sensor type; raw 3 = signal not available (SNA)";
CM_ SG_ 782 PARK_status2Counter "Parking assist sensors: status2 counter";
CM_ SG_ 782 PARK_status2Checksum "Parking assist sensors: status2 checksum";
CM_ BO_ 1630 "Parking assist sensors message: uds response";
CM_ SG_ 1630 PARK_udsResponseData "Parking assist sensors: uds response data";
CM_ BO_ 894 "Parking assist sensors message: warning matrix";
CM_ SG_ 894 PARK_matrixIndex "Parking assist sensors: matrix index";
CM_ SG_ 894 PARK_a001_s1_overTemp "Parking assist sensors: a001 s1 over temp";
CM_ SG_ 894 PARK_a002_s1_internalFail "Parking assist sensors: a002 s1 internal fail";
CM_ SG_ 894 PARK_a003_s1_linCommError "Parking assist sensors: a003 s1 lin comm error";
CM_ SG_ 894 PARK_a004_s1_blocked "Parking assist sensors: a004 s1 blocked";
CM_ SG_ 894 PARK_a005_s1_crossTalk "Parking assist sensors: a005 s1 cross talk";
CM_ SG_ 894 PARK_a006_s2_overTemp "Parking assist sensors: a006 s2 over temp";
CM_ SG_ 894 PARK_a007_s2_internalFail "Parking assist sensors: a007 s2 internal fail";
CM_ SG_ 894 PARK_a008_s2_linCommError "Parking assist sensors: a008 s2 lin comm error";
CM_ SG_ 894 PARK_a009_s2_blocked "Parking assist sensors: a009 s2 blocked";
CM_ SG_ 894 PARK_a010_s2_crossTalk "Parking assist sensors: a010 s2 cross talk";
CM_ SG_ 894 PARK_a011_s3_overTemp "Parking assist sensors: a011 s3 over temp";
CM_ SG_ 894 PARK_a012_s3_internalFail "Parking assist sensors: a012 s3 internal fail";
CM_ SG_ 894 PARK_a013_s3_linCommError "Parking assist sensors: a013 s3 lin comm error";
CM_ SG_ 894 PARK_a014_s3_blocked "Parking assist sensors: a014 s3 blocked";
CM_ SG_ 894 PARK_a015_s3_crossTalk "Parking assist sensors: a015 s3 cross talk";
CM_ SG_ 894 PARK_a016_s4_overTemp "Parking assist sensors: a016 s4 over temp";
CM_ SG_ 894 PARK_a017_s4_internalFail "Parking assist sensors: a017 s4 internal fail";
CM_ SG_ 894 PARK_a018_s4_linCommError "Parking assist sensors: a018 s4 lin comm error";
CM_ SG_ 894 PARK_a019_s4_blocked "Parking assist sensors: a019 s4 blocked";
CM_ SG_ 894 PARK_a020_s4_crossTalk "Parking assist sensors: a020 s4 cross talk";
CM_ SG_ 894 PARK_a021_s5_overTemp "Parking assist sensors: a021 s5 over temp";
CM_ SG_ 894 PARK_a022_s5_internalFail "Parking assist sensors: a022 s5 internal fail";
CM_ SG_ 894 PARK_a023_s5_linCommError "Parking assist sensors: a023 s5 lin comm error";
CM_ SG_ 894 PARK_a024_s5_blocked "Parking assist sensors: a024 s5 blocked";
CM_ SG_ 894 PARK_a025_s5_crossTalk "Parking assist sensors: a025 s5 cross talk";
CM_ SG_ 894 PARK_a026_s6_overTemp "Parking assist sensors: a026 s6 over temp";
CM_ SG_ 894 PARK_a027_s6_internalFail "Parking assist sensors: a027 s6 internal fail";
CM_ SG_ 894 PARK_a028_s6_linCommError "Parking assist sensors: a028 s6 lin comm error";
CM_ SG_ 894 PARK_a029_s6_blocked "Parking assist sensors: a029 s6 blocked";
CM_ SG_ 894 PARK_a030_s6_crossTalk "Parking assist sensors: a030 s6 cross talk";
CM_ SG_ 894 PARK_a031_s7_overTemp "Parking assist sensors: a031 s7 over temp";
CM_ SG_ 894 PARK_a032_s7_internalFail "Parking assist sensors: a032 s7 internal fail";
CM_ SG_ 894 PARK_a033_s7_linCommError "Parking assist sensors: a033 s7 lin comm error";
CM_ SG_ 894 PARK_a034_s7_blocked "Parking assist sensors: a034 s7 blocked";
CM_ SG_ 894 PARK_a035_s7_crossTalk "Parking assist sensors: a035 s7 cross talk";
CM_ SG_ 894 PARK_a036_s8_overTemp "Parking assist sensors: a036 s8 over temp";
CM_ SG_ 894 PARK_a037_s8_internalFail "Parking assist sensors: a037 s8 internal fail";
CM_ SG_ 894 PARK_a038_s8_linCommError "Parking assist sensors: a038 s8 lin comm error";
CM_ SG_ 894 PARK_a039_s8_blocked "Parking assist sensors: a039 s8 blocked";
CM_ SG_ 894 PARK_a040_s8_crossTalk "Parking assist sensors: a040 s8 cross talk";
CM_ SG_ 894 PARK_a041_s9_overTemp "Parking assist sensors: a041 s9 over temp";
CM_ SG_ 894 PARK_a042_s9_internalFail "Parking assist sensors: a042 s9 internal fail";
CM_ SG_ 894 PARK_a043_s9_linCommError "Parking assist sensors: a043 s9 lin comm error";
CM_ SG_ 894 PARK_a044_s9_blocked "Parking assist sensors: a044 s9 blocked";
CM_ SG_ 894 PARK_a045_s9_crossTalk "Parking assist sensors: a045 s9 cross talk";
CM_ SG_ 894 PARK_a046_s10_overTemp "Parking assist sensors: a046 s10 over temp";
CM_ SG_ 894 PARK_a047_s10_internalFail "Parking assist sensors: a047 s10 internal fail";
CM_ SG_ 894 PARK_a048_s10_linCommError "Parking assist sensors: a048 s10 lin comm error";
CM_ SG_ 894 PARK_a049_s10_blocked "Parking assist sensors: a049 s10 blocked";
CM_ SG_ 894 PARK_a050_s10_crossTalk "Parking assist sensors: a050 s10 cross talk";
CM_ SG_ 894 PARK_a051_s11_overTemp "Parking assist sensors: a051 s11 over temp";
CM_ SG_ 894 PARK_a052_s11_internalFail "Parking assist sensors: a052 s11 internal fail";
CM_ SG_ 894 PARK_a053_s11_linCommError "Parking assist sensors: a053 s11 lin comm error";
CM_ SG_ 894 PARK_a054_s11_blocked "Parking assist sensors: a054 s11 blocked";
CM_ SG_ 894 PARK_a055_s11_crossTalk "Parking assist sensors: a055 s11 cross talk";
CM_ SG_ 894 PARK_a056_s12_overTemp "Parking assist sensors: a056 s12 over temp";
CM_ SG_ 894 PARK_a057_s12_internalFail "Parking assist sensors: a057 s12 internal fail";
CM_ SG_ 894 PARK_a058_s12_linCommError "Parking assist sensors: a058 s12 lin comm error";
CM_ SG_ 894 PARK_a059_s12_blocked "Parking assist sensors: a059 s12 blocked";
CM_ SG_ 894 PARK_a060_s12_crossTalk "Parking assist sensors: a060 s12 cross talk";
CM_ SG_ 894 PARK_a061_ecuUnderVoltage "Parking assist sensors: a061 ecu under voltage";
CM_ SG_ 894 PARK_a062_ecuOverVoltage "Parking assist sensors: a062 ecu over voltage";
CM_ SG_ 894 PARK_a063_sensorVoltage "Parking assist sensors: a063 sensor voltage";
CM_ SG_ 894 PARK_a064_ecuFault "Parking assist sensors: a064 ecu fault";
CM_ SG_ 894 PARK_a065_crcFault "Parking assist sensors: a065 crc fault";
CM_ SG_ 894 PARK_a066_calibrationMissing "Parking assist sensors: a066 calibration missing";
CM_ SG_ 894 PARK_a067_privateCANBusOff "Parking assist sensors: a067 private CAN bus off";
CM_ SG_ 894 PARK_a068_hardwareWatchDog "Parking assist sensors: a068 hardware watch dog";
CM_ SG_ 894 PARK_a069_dasMia "Parking assist sensors: a069 das mia";
CM_ SG_ 894 PARK_a070_sccmMia "Parking assist sensors: a070 sccm mia";
CM_ SG_ 894 PARK_a071_diMia "Parking assist sensors: a071 di mia";
CM_ SG_ 894 PARK_a072_epasMia "Parking assist sensors: a072 epas mia";
CM_ SG_ 894 PARK_a073_epbMia "Parking assist sensors: a073 epb mia";
CM_ SG_ 894 PARK_a074_espMia "Parking assist sensors: a074 esp mia";
CM_ SG_ 894 PARK_a075_rcmMia "Parking assist sensors: a075 rcm mia";
CM_ SG_ 894 PARK_a076_vcFrontMia "Parking assist sensors: a076 vc front mia";
CM_ SG_ 894 PARK_a077_dasError "Parking assist sensors: a077 das error";
CM_ SG_ 894 PARK_a078_diError "Parking assist sensors: a078 di error";
CM_ SG_ 894 PARK_a079_epasError "Parking assist sensors: a079 epas error";
CM_ SG_ 894 PARK_a080_epbError "Parking assist sensors: a080 epb error";
CM_ SG_ 894 PARK_a081_espError "Parking assist sensors: a081 esp error";
CM_ SG_ 894 PARK_a082_rcmError "Parking assist sensors: a082 rcm error";
CM_ SG_ 894 PARK_a083_vcFrontError "Parking assist sensors: a083 vc front error";
CM_ SG_ 894 PARK_a084_sccmError "Parking assist sensors: a084 sccm error";
CM_ SG_ 894 PARK_a085_watchdogReset "Parking assist sensors: a085 watchdog reset";
CM_ SG_ 894 PARK_a086_nvmFault "Parking assist sensors: a086 nvm fault";
CM_ SG_ 894 PARK_a087_sensorMismatchError "Parking assist sensors: a087 sensor mismatch error";
BA_DEF_ BO_ "GenMsgCycleTime" INT 0 3600000;
BA_DEF_ BO_ "GenMsgSendType" ENUM "Cyclic","NotUsed","NotUsed","NotUsed","NotUsed","NotUsed","NotUsed","IfActive","NoMsgSendType","NotUsed";
BA_DEF_ BO_ "VFrameFormat" ENUM "StandardCAN","ExtendedCAN","reserved","J1939PG","reserved","reserved","reserved","reserved","reserved","reserved","reserved","reserved","reserved","reserved","StandardCAN_FD","ExtendedCAN_FD";
BA_DEF_ BO_ "CANFD_BRS" ENUM "0","1";
BA_DEF_ SG_ "GenSigSNA" STRING;
BA_DEF_ SG_ "SystemSignalLongSymbol" STRING;
BA_DEF_ SG_ "Confidence" ENUM "validated","plausible","layout-only","contradicted";
BA_DEF_DEF_ "GenMsgCycleTime" 0;
BA_DEF_DEF_ "GenMsgSendType" "NoMsgSendType";
BA_DEF_DEF_ "VFrameFormat" "StandardCAN";
BA_DEF_DEF_ "CANFD_BRS" "1";
BA_DEF_DEF_ "GenSigSNA" "";
BA_DEF_DEF_ "SystemSignalLongSymbol" "";
BA_DEF_DEF_ "Confidence" "layout-only";
BA_ "GenMsgCycleTime" BO_ 846 100;
BA_ "GenMsgSendType" BO_ 846 0;
BA_ "GenMsgCycleTime" BO_ 862 100;
BA_ "GenMsgSendType" BO_ 862 0;
BA_ "GenMsgCycleTime" BO_ 926 100;
BA_ "GenMsgSendType" BO_ 926 0;
BA_ "GenMsgCycleTime" BO_ 606 100;
BA_ "GenMsgSendType" BO_ 606 0;
BA_ "GenMsgCycleTime" BO_ 542 40;
BA_ "GenMsgSendType" BO_ 542 0;
BA_ "GenMsgCycleTime" BO_ 590 100;
BA_ "GenMsgSendType" BO_ 590 0;
BA_ "GenMsgCycleTime" BO_ 526 40;
BA_ "GenMsgSendType" BO_ 526 0;
BA_ "GenMsgCycleTime" BO_ 558 40;
BA_ "GenMsgSendType" BO_ 558 0;
BA_ "GenMsgCycleTime" BO_ 814 100;
BA_ "GenMsgSendType" BO_ 814 0;
BA_ "GenMsgCycleTime" BO_ 830 100;
BA_ "GenMsgSendType" BO_ 830 0;
BA_ "GenMsgCycleTime" BO_ 799 500;
BA_ "GenMsgSendType" BO_ 799 0;
BA_ "GenMsgCycleTime" BO_ 782 250;
BA_ "GenMsgSendType" BO_ 782 0;
BA_ "GenMsgCycleTime" BO_ 894 1000;
BA_ "GenMsgSendType" BO_ 894 0;
BA_ "Confidence" SG_ 846 PARK_frontLeftMiddleRawDistData 0;
BA_ "GenSigSNA" SG_ 846 PARK_frontLeftMiddleRawDistData "255";
BA_ "Confidence" SG_ 846 PARK_frontMiddleRawDistData 0;
BA_ "GenSigSNA" SG_ 846 PARK_frontMiddleRawDistData "255";
BA_ "Confidence" SG_ 846 PARK_frontRightMiddleRawDistData 0;
BA_ "GenSigSNA" SG_ 846 PARK_frontRightMiddleRawDistData "255";
BA_ "Confidence" SG_ 846 PARK_pasFrontMiddleCounter 0;
BA_ "Confidence" SG_ 846 PARK_pasFrontMiddleChecksum 0;
BA_ "Confidence" SG_ 862 PARK_rearLeftMiddleRawDistData 0;
BA_ "GenSigSNA" SG_ 862 PARK_rearLeftMiddleRawDistData "255";
BA_ "Confidence" SG_ 862 PARK_rearMiddleRawDistData 0;
BA_ "GenSigSNA" SG_ 862 PARK_rearMiddleRawDistData "255";
BA_ "Confidence" SG_ 862 PARK_rearRightMiddleRawDistData 0;
BA_ "GenSigSNA" SG_ 862 PARK_rearRightMiddleRawDistData "255";
BA_ "Confidence" SG_ 862 PARK_pasRearMiddleCounter 0;
BA_ "Confidence" SG_ 862 PARK_pasRearMiddleChecksum 0;
BA_ "Confidence" SG_ 926 PARK_rightSideFrontRawDistData 0;
BA_ "GenSigSNA" SG_ 926 PARK_rightSideFrontRawDistData "255";
BA_ "Confidence" SG_ 926 PARK_rightSideRearRawDistData 0;
BA_ "GenSigSNA" SG_ 926 PARK_rightSideRearRawDistData "255";
BA_ "Confidence" SG_ 926 PARK_leftSideFrontRawDistData 0;
BA_ "GenSigSNA" SG_ 926 PARK_leftSideFrontRawDistData "255";
BA_ "Confidence" SG_ 926 PARK_leftSideRearRawDistData 0;
BA_ "GenSigSNA" SG_ 926 PARK_leftSideRearRawDistData "255";
BA_ "Confidence" SG_ 926 PARK_pasSidesCounter 0;
BA_ "Confidence" SG_ 926 PARK_pasSidesChecksum 0;
BA_ "Confidence" SG_ 606 PARK_pscEnvSlotType 1;
BA_ "Confidence" SG_ 606 PARK_pscLeftParallelObj1X 0;
BA_ "GenSigSNA" SG_ 606 PARK_pscLeftParallelObj1X "2047";
BA_ "Confidence" SG_ 606 PARK_pscLeftParallelObj1Y 0;
BA_ "GenSigSNA" SG_ 606 PARK_pscLeftParallelObj1Y "2047";
BA_ "Confidence" SG_ 606 PARK_pscLeftParallelObj1Alpha 0;
BA_ "GenSigSNA" SG_ 606 PARK_pscLeftParallelObj1Alpha "127";
BA_ "Confidence" SG_ 606 PARK_pscLeftParallelObj2Y 0;
BA_ "GenSigSNA" SG_ 606 PARK_pscLeftParallelObj2Y "2047";
BA_ "Confidence" SG_ 606 PARK_pscLeftParallelObj2X 0;
BA_ "GenSigSNA" SG_ 606 PARK_pscLeftParallelObj2X "2047";
BA_ "Confidence" SG_ 606 PARK_pscLeftParallelObj2Alpha 0;
BA_ "GenSigSNA" SG_ 606 PARK_pscLeftParallelObj2Alpha "127";
BA_ "Confidence" SG_ 606 PARK_pscLeftCrossObj1X 0;
BA_ "GenSigSNA" SG_ 606 PARK_pscLeftCrossObj1X "2047";
BA_ "Confidence" SG_ 606 PARK_pscLeftCrossObj1Y 0;
BA_ "GenSigSNA" SG_ 606 PARK_pscLeftCrossObj1Y "2047";
BA_ "Confidence" SG_ 606 PARK_pscLeftCrossObj1Alpha 0;
BA_ "GenSigSNA" SG_ 606 PARK_pscLeftCrossObj1Alpha "127";
BA_ "Confidence" SG_ 606 PARK_pscLeftCrossObj2Y 0;
BA_ "GenSigSNA" SG_ 606 PARK_pscLeftCrossObj2Y "2047";
BA_ "Confidence" SG_ 606 PARK_pscLeftCrossObj2X 0;
BA_ "GenSigSNA" SG_ 606 PARK_pscLeftCrossObj2X "2047";
BA_ "Confidence" SG_ 606 PARK_pscLeftCrossObj2Alpha 0;
BA_ "GenSigSNA" SG_ 606 PARK_pscLeftCrossObj2Alpha "127";
BA_ "Confidence" SG_ 606 PARK_pscRightParallelObj1X 0;
BA_ "GenSigSNA" SG_ 606 PARK_pscRightParallelObj1X "2047";
BA_ "Confidence" SG_ 606 PARK_pscRightParallelObj1Y 0;
BA_ "GenSigSNA" SG_ 606 PARK_pscRightParallelObj1Y "2047";
BA_ "Confidence" SG_ 606 PARK_pscRightParallelObj1Alpha 0;
BA_ "GenSigSNA" SG_ 606 PARK_pscRightParallelObj1Alpha "127";
BA_ "Confidence" SG_ 606 PARK_pscRightParallelObj2Y 0;
BA_ "GenSigSNA" SG_ 606 PARK_pscRightParallelObj2Y "2047";
BA_ "Confidence" SG_ 606 PARK_pscRightParallelObj2X 0;
BA_ "GenSigSNA" SG_ 606 PARK_pscRightParallelObj2X "2047";
BA_ "Confidence" SG_ 606 PARK_pscRightParallelObj2Alpha 0;
BA_ "GenSigSNA" SG_ 606 PARK_pscRightParallelObj2Alpha "127";
BA_ "Confidence" SG_ 606 PARK_pscRightCrossObj1X 0;
BA_ "GenSigSNA" SG_ 606 PARK_pscRightCrossObj1X "2047";
BA_ "Confidence" SG_ 606 PARK_pscRightCrossObj1Y 0;
BA_ "GenSigSNA" SG_ 606 PARK_pscRightCrossObj1Y "2047";
BA_ "Confidence" SG_ 606 PARK_pscRightCrossObj1Alpha 0;
BA_ "GenSigSNA" SG_ 606 PARK_pscRightCrossObj1Alpha "127";
BA_ "Confidence" SG_ 606 PARK_pscRightCrossObj2Y 0;
BA_ "GenSigSNA" SG_ 606 PARK_pscRightCrossObj2Y "2047";
BA_ "Confidence" SG_ 606 PARK_pscRightCrossObj2X 0;
BA_ "GenSigSNA" SG_ 606 PARK_pscRightCrossObj2X "2047";
BA_ "Confidence" SG_ 606 PARK_pscRightCrossObj2Alpha 0;
BA_ "GenSigSNA" SG_ 606 PARK_pscRightCrossObj2Alpha "127";
BA_ "Confidence" SG_ 542 PARK_pscParkStatus 0;
BA_ "GenSigSNA" SG_ 542 PARK_pscParkStatus "7";
BA_ "Confidence" SG_ 542 PARK_pscParkAbortReason 0;
BA_ "GenSigSNA" SG_ 542 PARK_pscParkAbortReason "31";
BA_ "Confidence" SG_ 542 PARK_pscParallelSpace 0;
BA_ "Confidence" SG_ 542 PARK_pscCrossSpace 0;
BA_ "Confidence" SG_ 542 PARK_pscParallelRightParkable 0;
BA_ "GenSigSNA" SG_ 542 PARK_pscParallelRightParkable "3";
BA_ "Confidence" SG_ 542 PARK_pscParallelLeftParkable 0;
BA_ "GenSigSNA" SG_ 542 PARK_pscParallelLeftParkable "3";
BA_ "Confidence" SG_ 542 PARK_pscCrossRightParkable 0;
BA_ "GenSigSNA" SG_ 542 PARK_pscCrossRightParkable "3";
BA_ "Confidence" SG_ 542 PARK_pscMaxVelocity 0;
BA_ "GenSigSNA" SG_ 542 PARK_pscMaxVelocity "63";
BA_ "Confidence" SG_ 542 PARK_pscCrossLeftParkable 0;
BA_ "GenSigSNA" SG_ 542 PARK_pscCrossLeftParkable "3";
BA_ "Confidence" SG_ 542 PARK_pscParkInstruction 0;
BA_ "GenSigSNA" SG_ 542 PARK_pscParkInstruction "7";
BA_ "Confidence" SG_ 542 PARK_pscManeuverDistance 0;
BA_ "GenSigSNA" SG_ 542 PARK_pscManeuverDistance "2047";
BA_ "Confidence" SG_ 542 PARK_pscAngleActive 0;
BA_ "Confidence" SG_ 542 PARK_pscAngleRequest 0;
BA_ "Confidence" SG_ 542 PARK_pscStatusCounter 0;
BA_ "Confidence" SG_ 542 PARK_pscStatusChecksum 0;
BA_ "Confidence" SG_ 590 PARK_pscVehSlotType 1;
BA_ "Confidence" SG_ 590 PARK_pscLeftParallelVehX 0;
BA_ "GenSigSNA" SG_ 590 PARK_pscLeftParallelVehX "2047";
BA_ "Confidence" SG_ 590 PARK_pscLeftParallelVehY 0;
BA_ "GenSigSNA" SG_ 590 PARK_pscLeftParallelVehY "2047";
BA_ "Confidence" SG_ 590 PARK_pscLeftParallelPsi 0;
BA_ "GenSigSNA" SG_ 590 PARK_pscLeftParallelPsi "8191";
BA_ "Confidence" SG_ 590 PARK_pscLeftParallelSizeX 0;
BA_ "GenSigSNA" SG_ 590 PARK_pscLeftParallelSizeX "255";
BA_ "Confidence" SG_ 590 PARK_pscLeftParallelSizeY 0;
BA_ "GenSigSNA" SG_ 590 PARK_pscLeftParallelSizeY "255";
BA_ "Confidence" SG_ 590 PARK_pscLeftCrossVehX 0;
BA_ "GenSigSNA" SG_ 590 PARK_pscLeftCrossVehX "2047";
BA_ "Confidence" SG_ 590 PARK_pscLeftCrossVehY 0;
BA_ "GenSigSNA" SG_ 590 PARK_pscLeftCrossVehY "2047";
BA_ "Confidence" SG_ 590 PARK_pscLeftCrossPsi 0;
BA_ "GenSigSNA" SG_ 590 PARK_pscLeftCrossPsi "8191";
BA_ "Confidence" SG_ 590 PARK_pscLeftCrossSizeX 0;
BA_ "GenSigSNA" SG_ 590 PARK_pscLeftCrossSizeX "255";
BA_ "Confidence" SG_ 590 PARK_pscLeftCrossSizeY 0;
BA_ "GenSigSNA" SG_ 590 PARK_pscLeftCrossSizeY "255";
BA_ "Confidence" SG_ 590 PARK_pscRightParallelVehX 0;
BA_ "GenSigSNA" SG_ 590 PARK_pscRightParallelVehX "2047";
BA_ "Confidence" SG_ 590 PARK_pscRightParallelVehY 0;
BA_ "GenSigSNA" SG_ 590 PARK_pscRightParallelVehY "2047";
BA_ "Confidence" SG_ 590 PARK_pscRightParallelPsi 0;
BA_ "GenSigSNA" SG_ 590 PARK_pscRightParallelPsi "8191";
BA_ "Confidence" SG_ 590 PARK_pscRightParallelSizeX 0;
BA_ "GenSigSNA" SG_ 590 PARK_pscRightParallelSizeX "255";
BA_ "Confidence" SG_ 590 PARK_pscRightParallelSizeY 0;
BA_ "GenSigSNA" SG_ 590 PARK_pscRightParallelSizeY "255";
BA_ "Confidence" SG_ 590 PARK_pscRightCrossVehX 0;
BA_ "GenSigSNA" SG_ 590 PARK_pscRightCrossVehX "2047";
BA_ "Confidence" SG_ 590 PARK_pscRightCrossVehY 0;
BA_ "GenSigSNA" SG_ 590 PARK_pscRightCrossVehY "2047";
BA_ "Confidence" SG_ 590 PARK_pscRightCrossPsi 0;
BA_ "GenSigSNA" SG_ 590 PARK_pscRightCrossPsi "8191";
BA_ "Confidence" SG_ 590 PARK_pscRightCrossSizeX 0;
BA_ "GenSigSNA" SG_ 590 PARK_pscRightCrossSizeX "255";
BA_ "Confidence" SG_ 590 PARK_pscRightCrossSizeY 0;
BA_ "GenSigSNA" SG_ 590 PARK_pscRightCrossSizeY "255";
BA_ "Confidence" SG_ 526 PARK_sdiSensor1RawDistData 0;
BA_ "GenSigSNA" SG_ 526 PARK_sdiSensor1RawDistData "511";
BA_ "Confidence" SG_ 526 PARK_sdiSensor2RawDistData 0;
BA_ "GenSigSNA" SG_ 526 PARK_sdiSensor2RawDistData "511";
BA_ "Confidence" SG_ 526 PARK_sdiSensor3RawDistData 0;
BA_ "GenSigSNA" SG_ 526 PARK_sdiSensor3RawDistData "511";
BA_ "Confidence" SG_ 526 PARK_sdiSensor4RawDistData 0;
BA_ "GenSigSNA" SG_ 526 PARK_sdiSensor4RawDistData "511";
BA_ "Confidence" SG_ 526 PARK_sdiSensor5RawDistData 0;
BA_ "GenSigSNA" SG_ 526 PARK_sdiSensor5RawDistData "511";
BA_ "Confidence" SG_ 526 PARK_sdiSensor6RawDistData 0;
BA_ "GenSigSNA" SG_ 526 PARK_sdiSensor6RawDistData "511";
BA_ "Confidence" SG_ 526 PARK_sdiFrontCounter 0;
BA_ "Confidence" SG_ 526 PARK_sdiFrontChecksum 0;
BA_ "Confidence" SG_ 558 PARK_sdiSensor7RawDistData 0;
BA_ "GenSigSNA" SG_ 558 PARK_sdiSensor7RawDistData "511";
BA_ "Confidence" SG_ 558 PARK_sdiSensor8RawDistData 0;
BA_ "GenSigSNA" SG_ 558 PARK_sdiSensor8RawDistData "511";
BA_ "Confidence" SG_ 558 PARK_sdiSensor9RawDistData 0;
BA_ "GenSigSNA" SG_ 558 PARK_sdiSensor9RawDistData "511";
BA_ "Confidence" SG_ 558 PARK_sdiSensor10RawDistData 0;
BA_ "GenSigSNA" SG_ 558 PARK_sdiSensor10RawDistData "511";
BA_ "Confidence" SG_ 558 PARK_sdiSensor11RawDistData 0;
BA_ "GenSigSNA" SG_ 558 PARK_sdiSensor11RawDistData "511";
BA_ "Confidence" SG_ 558 PARK_sdiSensor12RawDistData 0;
BA_ "GenSigSNA" SG_ 558 PARK_sdiSensor12RawDistData "511";
BA_ "Confidence" SG_ 558 PARK_sdiRearCounter 0;
BA_ "Confidence" SG_ 558 PARK_sdiRearChecksum 0;
BA_ "Confidence" SG_ 814 PARK_frontRightSensorState 0;
BA_ "GenSigSNA" SG_ 814 PARK_frontRightSensorState "3";
BA_ "Confidence" SG_ 814 PARK_frontRightMiddleSensorState 0;
BA_ "GenSigSNA" SG_ 814 PARK_frontRightMiddleSensorState "3";
BA_ "Confidence" SG_ 814 PARK_frontLeftMiddleSensorState 0;
BA_ "GenSigSNA" SG_ 814 PARK_frontLeftMiddleSensorState "3";
BA_ "Confidence" SG_ 814 PARK_frontLeftSensorState 0;
BA_ "GenSigSNA" SG_ 814 PARK_frontLeftSensorState "3";
BA_ "Confidence" SG_ 814 PARK_frontLeftRawDistData 0;
BA_ "GenSigSNA" SG_ 814 PARK_frontLeftRawDistData "255";
BA_ "Confidence" SG_ 814 PARK_frontRightRawDistData 0;
BA_ "GenSigSNA" SG_ 814 PARK_frontRightRawDistData "255";
BA_ "Confidence" SG_ 814 PARK_systemStatusFront 0;
BA_ "GenSigSNA" SG_ 814 PARK_systemStatusFront "3";
BA_ "Confidence" SG_ 814 PARK_frontDtcPresent 0;
BA_ "GenSigSNA" SG_ 814 PARK_frontDtcPresent "3";
BA_ "Confidence" SG_ 814 PARK_sensorStatusFrontCounter 0;
BA_ "Confidence" SG_ 814 PARK_sensorStatusFrontChecksum 0;
BA_ "Confidence" SG_ 830 PARK_rearRightSensorState 0;
BA_ "GenSigSNA" SG_ 830 PARK_rearRightSensorState "3";
BA_ "Confidence" SG_ 830 PARK_rearRightMiddleSensorState 0;
BA_ "GenSigSNA" SG_ 830 PARK_rearRightMiddleSensorState "3";
BA_ "Confidence" SG_ 830 PARK_rearLeftMiddleSensorState 0;
BA_ "GenSigSNA" SG_ 830 PARK_rearLeftMiddleSensorState "3";
BA_ "Confidence" SG_ 830 PARK_rearLeftSensorState 0;
BA_ "GenSigSNA" SG_ 830 PARK_rearLeftSensorState "3";
BA_ "Confidence" SG_ 830 PARK_rearLeftRawDistData 0;
BA_ "GenSigSNA" SG_ 830 PARK_rearLeftRawDistData "255";
BA_ "Confidence" SG_ 830 PARK_rearRightRawDistData 0;
BA_ "GenSigSNA" SG_ 830 PARK_rearRightRawDistData "255";
BA_ "Confidence" SG_ 830 PARK_systemStatusRear 0;
BA_ "GenSigSNA" SG_ 830 PARK_systemStatusRear "3";
BA_ "Confidence" SG_ 830 PARK_rearDtcPresent 0;
BA_ "GenSigSNA" SG_ 830 PARK_rearDtcPresent "3";
BA_ "Confidence" SG_ 830 PARK_sensorStatusRearCounter 0;
BA_ "Confidence" SG_ 830 PARK_sensorStatusRearChecksum 0;
BA_ "Confidence" SG_ 799 PARK_status 0;
BA_ "GenSigSNA" SG_ 799 PARK_status "3";
BA_ "Confidence" SG_ 799 PARK_serviceRequest 0;
BA_ "GenSigSNA" SG_ 799 PARK_serviceRequest "3";
BA_ "Confidence" SG_ 799 PARK_systemDtcPresent 0;
BA_ "GenSigSNA" SG_ 799 PARK_systemDtcPresent "3";
BA_ "Confidence" SG_ 799 PARK_statusCounter 0;
BA_ "Confidence" SG_ 799 PARK_statusChecksum 0;
BA_ "Confidence" SG_ 799 PARK_majorVersion 0;
BA_ "GenSigSNA" SG_ 799 PARK_majorVersion "255";
BA_ "Confidence" SG_ 799 PARK_minorVersion 0;
BA_ "GenSigSNA" SG_ 799 PARK_minorVersion "255";
BA_ "Confidence" SG_ 799 PARK_subMinorVersion 0;
BA_ "GenSigSNA" SG_ 799 PARK_subMinorVersion "255";
BA_ "Confidence" SG_ 782 PARK_frontSVACharID 0;
BA_ "Confidence" SG_ 782 PARK_pscRightCurbType 0;
BA_ "Confidence" SG_ 782 PARK_rearSVACharID 0;
BA_ "Confidence" SG_ 782 PARK_pscLeftCurbType 0;
BA_ "Confidence" SG_ 782 PARK_autoCalComplete 0;
BA_ "Confidence" SG_ 782 PARK_geometryType 0;
BA_ "Confidence" SG_ 782 PARK_tireFitment 0;
BA_ "GenSigSNA" SG_ 782 PARK_tireFitment "3";
BA_ "Confidence" SG_ 782 PARK_rackDetected 0;
BA_ "GenSigSNA" SG_ 782 PARK_rackDetected "3";
BA_ "Confidence" SG_ 782 PARK_sdiActive 0;
BA_ "Confidence" SG_ 782 PARK_sdiNoise 0;
BA_ "GenSigSNA" SG_ 782 PARK_sdiNoise "3";
BA_ "Confidence" SG_ 782 PARK_sdiBlindSpotRight 0;
BA_ "GenSigSNA" SG_ 782 PARK_sdiBlindSpotRight "3";
BA_ "Confidence" SG_ 782 PARK_sdiBlindSpotLeft 0;
BA_ "GenSigSNA" SG_ 782 PARK_sdiBlindSpotLeft "3";
BA_ "Confidence" SG_ 782 PARK_sensorType 0;
BA_ "GenSigSNA" SG_ 782 PARK_sensorType "3";
BA_ "Confidence" SG_ 782 PARK_status2Counter 0;
BA_ "Confidence" SG_ 782 PARK_status2Checksum 0;
BA_ "Confidence" SG_ 1630 PARK_udsResponseData 1;
BA_ "Confidence" SG_ 894 PARK_matrixIndex 1;
VAL_ 846 PARK_frontLeftMiddleRawDistData 255 "SNA" ;
VAL_ 846 PARK_frontMiddleRawDistData 255 "SNA" ;
VAL_ 846 PARK_frontRightMiddleRawDistData 255 "SNA" ;
VAL_ 862 PARK_rearLeftMiddleRawDistData 255 "SNA" ;
VAL_ 862 PARK_rearMiddleRawDistData 255 "SNA" ;
VAL_ 862 PARK_rearRightMiddleRawDistData 255 "SNA" ;
VAL_ 926 PARK_rightSideFrontRawDistData 255 "SNA" ;
VAL_ 926 PARK_rightSideRearRawDistData 255 "SNA" ;
VAL_ 926 PARK_leftSideFrontRawDistData 255 "SNA" ;
VAL_ 926 PARK_leftSideRearRawDistData 255 "SNA" ;
VAL_ 606 PARK_pscEnvSlotType 3 "RIGHT_CROSS" 2 "RIGHT_PARALLEL" 1 "LEFT_CROSS" 0 "LEFT_PARALLEL" ;
VAL_ 606 PARK_pscLeftParallelObj1X 2047 "SNA" 2046 "NO_SPACE" ;
VAL_ 606 PARK_pscLeftParallelObj1Y 2047 "SNA" 2046 "NO_SPACE" ;
VAL_ 606 PARK_pscLeftParallelObj1Alpha 127 "SNA" 126 "NO_SPACE" ;
VAL_ 606 PARK_pscLeftParallelObj2Y 2047 "SNA" 2046 "NO_SPACE" ;
VAL_ 606 PARK_pscLeftParallelObj2X 2047 "SNA" 2046 "NO_SPACE" ;
VAL_ 606 PARK_pscLeftParallelObj2Alpha 127 "SNA" 126 "NO_SPACE" ;
VAL_ 606 PARK_pscLeftCrossObj1X 2047 "SNA" 2046 "NO_SPACE" ;
VAL_ 606 PARK_pscLeftCrossObj1Y 2047 "SNA" 2046 "NO_SPACE" ;
VAL_ 606 PARK_pscLeftCrossObj1Alpha 127 "SNA" 126 "NO_SPACE" ;
VAL_ 606 PARK_pscLeftCrossObj2Y 2047 "SNA" 2046 "NO_SPACE" ;
VAL_ 606 PARK_pscLeftCrossObj2X 2047 "SNA" 2046 "NO_SPACE" ;
VAL_ 606 PARK_pscLeftCrossObj2Alpha 127 "SNA" 126 "NO_SPACE" ;
VAL_ 606 PARK_pscRightParallelObj1X 2047 "SNA" 2046 "NO_SPACE" ;
VAL_ 606 PARK_pscRightParallelObj1Y 2047 "SNA" 2046 "NO_SPACE" ;
VAL_ 606 PARK_pscRightParallelObj1Alpha 127 "SNA" 126 "NO_SPACE" ;
VAL_ 606 PARK_pscRightParallelObj2Y 2047 "SNA" 2046 "NO_SPACE" ;
VAL_ 606 PARK_pscRightParallelObj2X 2047 "SNA" 2046 "NO_SPACE" ;
VAL_ 606 PARK_pscRightParallelObj2Alpha 127 "SNA" 126 "NO_SPACE" ;
VAL_ 606 PARK_pscRightCrossObj1X 2047 "SNA" 2046 "NO_SPACE" ;
VAL_ 606 PARK_pscRightCrossObj1Y 2047 "SNA" 2046 "NO_SPACE" ;
VAL_ 606 PARK_pscRightCrossObj1Alpha 127 "SNA" 126 "NO_SPACE" ;
VAL_ 606 PARK_pscRightCrossObj2Y 2047 "SNA" 2046 "NO_SPACE" ;
VAL_ 606 PARK_pscRightCrossObj2X 2047 "SNA" 2046 "NO_SPACE" ;
VAL_ 606 PARK_pscRightCrossObj2Alpha 127 "SNA" 126 "NO_SPACE" ;
VAL_ 542 PARK_pscParkStatus 7 "SNA" 6 "FAULT" 5 "GUIDANCE_FINISHED" 4 "PRE_GUIDANCE" 3 "GUIDANCE_RIGHT" 2 "GUIDANCE_LEFT" 1 "SEARCHING" 0 "NOT_AVAILABLE" ;
VAL_ 542 PARK_pscParkAbortReason 31 "SNA" 25 "PSC_MOVEMENT_AT_ACTIVATION" 24 "PSC_MAX_WAY_BEHIND_HINT" 23 "PSC_PARK_STC_FAILED" 22 "PSC_PARK_PONR_NOT_REACHED" 21 "PSC_VCTL_GENERAL_ABORT" 20 "PSC_HIGH_TORQUE" 19 "PSC_ASYNC_CTRL_SYSTEM" 18 "ERROR" 17 "SYSTEM_SERVICE" 16 "SYSTEM_FAULT" 15 "ECU_INTERNAL_FAULT" 14 "DAS_ABORT" 13 "EPAS_FAULT" 12 "VEHICLE_DYNAMICS_INTERVENTION" 11 "HANDS_ON_DETECTED" 10 "FULL_WARNING_ON_BOTH_SIDES" 9 "PARK_SPACE_TOO_SMALL" 8 "OBSTACLE_ON_PATH" 7 "MAX_YAW_ANGLE_REACHED" 6 "MAX_SWA_DEV_EXCEEDED" 5 "OFF_TRACK" 4 "UNCONTROLLED_TRAVEL_DIST_REACHED" 3 "NO_VALID_PATH" 2 "MAX_NUM_OF_MOVES" 1 "VELOCITY_TOO_HIGH" 0 "NONE" ;
VAL_ 542 PARK_pscParallelSpace 3 "BOTH_AVAILABLE" 2 "LEFT_AVAILABLE" 1 "RIGHT_AVAILABLE" 0 "NONE_AVAILABLE" ;
VAL_ 542 PARK_pscCrossSpace 3 "BOTH_AVAILABLE" 2 "LEFT_AVAILABLE" 1 "RIGHT_AVAILABLE" 0 "NONE_AVAILABLE" ;
VAL_ 542 PARK_pscParallelRightParkable 3 "SNA" 2 "PARKING_SLOT_OK_POSITION_OK" 1 "PARKING_SLOT_OK" 0 "NONE" ;
VAL_ 542 PARK_pscParallelLeftParkable 3 "SNA" 2 "PARKING_SLOT_OK_POSITION_OK" 1 "PARKING_SLOT_OK" 0 "NONE" ;
VAL_ 542 PARK_pscCrossRightParkable 3 "SNA" 2 "PARKING_SLOT_OK_POSITION_OK" 1 "PARKING_SLOT_OK" 0 "NONE" ;
VAL_ 542 PARK_pscMaxVelocity 63 "SNA" ;
VAL_ 542 PARK_pscCrossLeftParkable 3 "SNA" 2 "PARKING_SLOT_OK_POSITION_OK" 1 "PARKING_SLOT_OK" 0 "NONE" ;
VAL_ 542 PARK_pscParkInstruction 7 "SNA" 5 "EXPLORATION" 4 "ABORTED" 3 "DRIVE_BACKWARD" 2 "DRIVE_FORWARD" 1 "STOP" 0 "NO_MESSAGE" ;
VAL_ 542 PARK_pscManeuverDistance 2047 "SNA" ;
VAL_ 542 PARK_pscAngleActive 1 "REQUEST_CONTROL" 0 "INACTIVE" ;
VAL_ 590 PARK_pscVehSlotType 3 "RIGHT_CROSS" 2 "RIGHT_PARALLEL" 1 "LEFT_CROSS" 0 "LEFT_PARALLEL" ;
VAL_ 590 PARK_pscLeftParallelVehX 2047 "SNA" 2046 "NO_SPACE" ;
VAL_ 590 PARK_pscLeftParallelVehY 2047 "SNA" 2046 "NO_SPACE" ;
VAL_ 590 PARK_pscLeftParallelPsi 8191 "SNA" 8190 "NO_SPACE" ;
VAL_ 590 PARK_pscLeftParallelSizeX 255 "SNA" 254 "NO_SPACE" ;
VAL_ 590 PARK_pscLeftParallelSizeY 255 "SNA" 254 "NO_SPACE" ;
VAL_ 590 PARK_pscLeftCrossVehX 2047 "SNA" 2046 "NO_SPACE" ;
VAL_ 590 PARK_pscLeftCrossVehY 2047 "SNA" 2046 "NO_SPACE" ;
VAL_ 590 PARK_pscLeftCrossPsi 8191 "SNA" 8190 "NO_SPACE" ;
VAL_ 590 PARK_pscLeftCrossSizeX 255 "SNA" 254 "NO_SPACE" ;
VAL_ 590 PARK_pscLeftCrossSizeY 255 "SNA" 254 "NO_SPACE" ;
VAL_ 590 PARK_pscRightParallelVehX 2047 "SNA" 2046 "NO_SPACE" ;
VAL_ 590 PARK_pscRightParallelVehY 2047 "SNA" 2046 "NO_SPACE" ;
VAL_ 590 PARK_pscRightParallelPsi 8191 "SNA" 8190 "NO_SPACE" ;
VAL_ 590 PARK_pscRightParallelSizeX 255 "SNA" 254 "NO_SPACE" ;
VAL_ 590 PARK_pscRightParallelSizeY 255 "SNA" 254 "NO_SPACE" ;
VAL_ 590 PARK_pscRightCrossVehX 2047 "SNA" 2046 "NO_SPACE" ;
VAL_ 590 PARK_pscRightCrossVehY 2047 "SNA" 2046 "NO_SPACE" ;
VAL_ 590 PARK_pscRightCrossPsi 8191 "SNA" 8190 "NO_SPACE" ;
VAL_ 590 PARK_pscRightCrossSizeX 255 "SNA" 254 "NO_SPACE" ;
VAL_ 590 PARK_pscRightCrossSizeY 255 "SNA" 254 "NO_SPACE" ;
VAL_ 526 PARK_sdiSensor1RawDistData 511 "SNA" 500 "NO_OBJECT_DETECTED" 1 "NEAR_DETECTION" 0 "BLOCKED" ;
VAL_ 526 PARK_sdiSensor2RawDistData 511 "SNA" 500 "NO_OBJECT_DETECTED" 1 "NEAR_DETECTION" 0 "BLOCKED" ;
VAL_ 526 PARK_sdiSensor3RawDistData 511 "SNA" 500 "NO_OBJECT_DETECTED" 1 "NEAR_DETECTION" 0 "BLOCKED" ;
VAL_ 526 PARK_sdiSensor4RawDistData 511 "SNA" 500 "NO_OBJECT_DETECTED" 1 "NEAR_DETECTION" 0 "BLOCKED" ;
VAL_ 526 PARK_sdiSensor5RawDistData 511 "SNA" 500 "NO_OBJECT_DETECTED" 1 "NEAR_DETECTION" 0 "BLOCKED" ;
VAL_ 526 PARK_sdiSensor6RawDistData 511 "SNA" 500 "NO_OBJECT_DETECTED" 1 "NEAR_DETECTION" 0 "BLOCKED" ;
VAL_ 558 PARK_sdiSensor7RawDistData 511 "SNA" 500 "NO_OBJECT_DETECTED" 1 "NEAR_DETECTION" 0 "BLOCKED" ;
VAL_ 558 PARK_sdiSensor8RawDistData 511 "SNA" 500 "NO_OBJECT_DETECTED" 1 "NEAR_DETECTION" 0 "BLOCKED" ;
VAL_ 558 PARK_sdiSensor9RawDistData 511 "SNA" 500 "NO_OBJECT_DETECTED" 1 "NEAR_DETECTION" 0 "BLOCKED" ;
VAL_ 558 PARK_sdiSensor10RawDistData 511 "SNA" 500 "NO_OBJECT_DETECTED" 1 "NEAR_DETECTION" 0 "BLOCKED" ;
VAL_ 558 PARK_sdiSensor11RawDistData 511 "SNA" 500 "NO_OBJECT_DETECTED" 1 "NEAR_DETECTION" 0 "BLOCKED" ;
VAL_ 558 PARK_sdiSensor12RawDistData 511 "SNA" 500 "NO_OBJECT_DETECTED" 1 "NEAR_DETECTION" 0 "BLOCKED" ;
VAL_ 814 PARK_frontRightSensorState 3 "SNA" 2 "TEMPORARY_FAILURE" 1 "PERMANENT_FAILURE" 0 "NO_FAILURE" ;
VAL_ 814 PARK_frontRightMiddleSensorState 3 "SNA" 2 "TEMPORARY_FAILURE" 1 "PERMANENT_FAILURE" 0 "NO_FAILURE" ;
VAL_ 814 PARK_frontLeftMiddleSensorState 3 "SNA" 2 "TEMPORARY_FAILURE" 1 "PERMANENT_FAILURE" 0 "NO_FAILURE" ;
VAL_ 814 PARK_frontLeftSensorState 3 "SNA" 2 "TEMPORARY_FAILURE" 1 "PERMANENT_FAILURE" 0 "NO_FAILURE" ;
VAL_ 814 PARK_frontLeftRawDistData 255 "SNA" ;
VAL_ 814 PARK_frontRightRawDistData 255 "SNA" ;
VAL_ 814 PARK_systemStatusFront 3 "SNA" 2 "UNUSED" 1 "ENABLED" 0 "DISABLED" ;
VAL_ 814 PARK_frontDtcPresent 3 "SNA" 2 "UNUSED" 1 "TRUE" 0 "FALSE" ;
VAL_ 830 PARK_rearRightSensorState 3 "SNA" 2 "TEMPORARY_FAILURE" 1 "PERMANENT_FAILURE" 0 "NO_FAILURE" ;
VAL_ 830 PARK_rearRightMiddleSensorState 3 "SNA" 2 "TEMPORARY_FAILURE" 1 "PERMANENT_FAILURE" 0 "NO_FAILURE" ;
VAL_ 830 PARK_rearLeftMiddleSensorState 3 "SNA" 2 "TEMPORARY_FAILURE" 1 "PERMANENT_FAILURE" 0 "NO_FAILURE" ;
VAL_ 830 PARK_rearLeftSensorState 3 "SNA" 2 "TEMPORARY_FAILURE" 1 "PERMANENT_FAILURE" 0 "NO_FAILURE" ;
VAL_ 830 PARK_rearLeftRawDistData 255 "SNA" ;
VAL_ 830 PARK_rearRightRawDistData 255 "SNA" ;
VAL_ 830 PARK_systemStatusRear 3 "SNA" 2 "UNUSED" 1 "ENABLED" 0 "DISABLED" ;
VAL_ 830 PARK_rearDtcPresent 3 "SNA" 2 "UNUSED" 1 "TRUE" 0 "FALSE" ;
VAL_ 799 PARK_status 3 "SNA" 2 "TEMPORARY_FAILURE" 1 "ENABLED" 0 "DISABLED" ;
VAL_ 799 PARK_serviceRequest 3 "SNA" 2 "UNUSED" 1 "FAILURE" 0 "NO_FAILURE" ;
VAL_ 799 PARK_systemDtcPresent 3 "SNA" 2 "UNUSED" 1 "TRUE" 0 "FALSE" ;
VAL_ 799 PARK_majorVersion 255 "SNA" ;
VAL_ 799 PARK_minorVersion 255 "SNA" ;
VAL_ 799 PARK_subMinorVersion 255 "SNA" ;
VAL_ 782 PARK_pscRightCurbType 2 "HIGH_CURB" 1 "LOW_CURB" 0 "VIRTUAL_CURB" ;
VAL_ 782 PARK_pscLeftCurbType 2 "HIGH_CURB" 1 "LOW_CURB" 0 "VIRTUAL_CURB" ;
VAL_ 782 PARK_autoCalComplete 1 "COMPLETE" 0 "INCOMPLETE" ;
VAL_ 782 PARK_geometryType 3 "MODELY" 2 "MODEL3" 1 "MODELX" 0 "MODELS" ;
VAL_ 782 PARK_tireFitment 3 "SNA" 2 "NOT_USED" 1 "STAGGERED" 0 "SQUARE" ;
VAL_ 782 PARK_rackDetected 3 "SNA" 2 "RACK_DETECTED" 1 "NO_RACK" 0 "UNKNOWN" ;
VAL_ 782 PARK_sdiActive 1 "SDI_ENABLED" 0 "SDI_DISABLED" ;
VAL_ 782 PARK_sdiNoise 3 "SDI_NOISE_SNA" 2 "SDI_NOISE_RAIN" 1 "SDI_NOISE_HIGH" 0 "SDI_NOISE_NOMINAL" ;
VAL_ 782 PARK_sdiBlindSpotRight 3 "SNA" 2 "UNUSED" 1 "WARNING" 0 "NO_WARNING" ;
VAL_ 782 PARK_sdiBlindSpotLeft 3 "SNA" 2 "UNUSED" 1 "WARNING" 0 "NO_WARNING" ;
VAL_ 782 PARK_sensorType 3 "SNA" 2 "VALEO_HP" 1 "VALEO_HPFL" 0 "NONE" ;
VAL_ 894 PARK_matrixIndex 1 "AlertMatrix1" 0 "AlertMatrix0" ;
